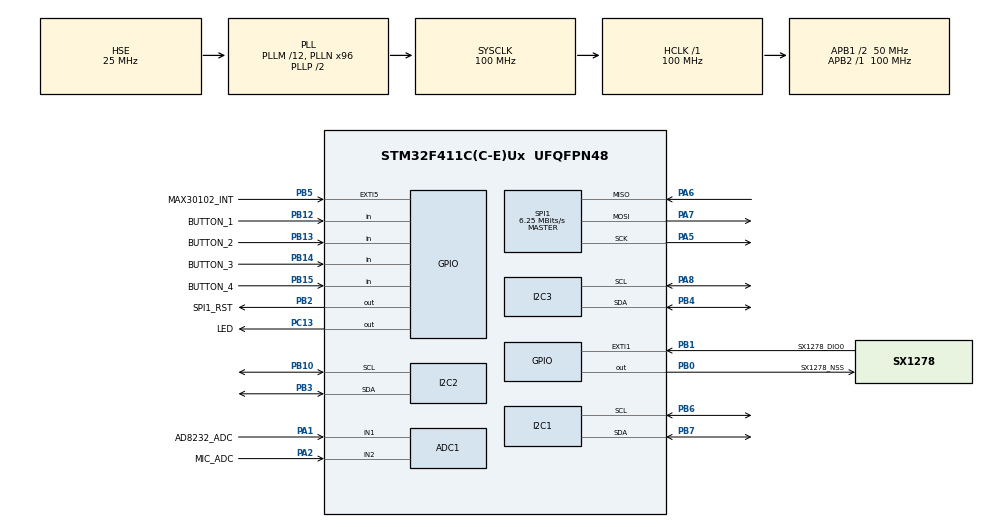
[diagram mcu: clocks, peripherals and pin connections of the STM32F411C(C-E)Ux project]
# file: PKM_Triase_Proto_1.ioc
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ADC1.Channel-1\#ChannelRegularConversion=ADC_CHANNEL_1
ADC1.Channel-2\#ChannelRegularConversion=ADC_CHANNEL_2
ADC1.ContinuousConvMode=DISABLE
ADC1.DMAContinuousRequests=ENABLE
ADC1.ExternalTrigConv=ADC_EXTERNALTRIGCONV_T2_TRGO
ADC1.NbrOfConversion=2
ADC1.NbrOfConversionFlag=1
ADC1.Rank-1\#ChannelRegularConversion=1
ADC1.Rank-2\#ChannelRegularConversion=2
ADC1.SamplingTime-1\#ChannelRegularConversion=ADC_SAMPLETIME_15CYCLES
ADC1.SamplingTime-2\#ChannelRegularConversion=ADC_SAMPLETIME_15CYCLES
ADC1.ScanConvMode=ENABLE
ADC1.master=1
Dma.ADC1.0.Direction=DMA_PERIPH_TO_MEMORY
Dma.ADC1.0.FIFOMode=DMA_FIFOMODE_DISABLE
Dma.ADC1.0.Instance=DMA2_Stream0
Dma.ADC1.0.MemDataAlignment=DMA_MDATAALIGN_HALFWORD
Dma.ADC1.0.MemInc=DMA_MINC_ENABLE
Dma.ADC1.0.Mode=DMA_CIRCULAR
Dma.ADC1.0.PeriphDataAlignment=DMA_PDATAALIGN_HALFWORD
Dma.ADC1.0.PeriphInc=DMA_PINC_DISABLE
Dma.ADC1.0.Priority=DMA_PRIORITY_LOW
Dma.Request0=ADC1
I2C2.I2C_Mode=I2C_Standard
Mcu.Family=STM32F4
Mcu.Name=STM32F411C(C-E)Ux
Mcu.Package=UFQFPN48
NVIC.ADC_IRQn=true\:0\:0\:false\:false\:true\:true\:true\:true
NVIC.DMA2_Stream0_IRQn=true\:0\:0\:false\:false\:true\:false\:true\:true
NVIC.EXTI9_5_IRQn=true\:0\:0\:false\:false\:true\:true\:true\:true
NVIC.I2C2_ER_IRQn=true\:0\:0\:false\:false\:true\:true\:true\:true
NVIC.I2C2_EV_IRQn=true\:0\:0\:false\:false\:true\:true\:true\:true
NVIC.PriorityGroup=NVIC_PRIORITYGROUP_4
NVIC.TIM1_UP_TIM10_IRQn=true\:0\:0\:true\:false\:true\:true\:true\:true
NVIC.TIM2_IRQn=true\:0\:0\:false\:false\:true\:true\:true\:true
PA1.GPIO_Label=AD8232_ADC
PA1.Signal=ADCx_IN1
PA2.GPIO_Label=MIC_ADC
PA2.Signal=ADCx_IN2
PA5.Mode=Full_Duplex_Master
PA5.Signal=SPI1_SCK
PA6.Mode=Full_Duplex_Master
PA6.Signal=SPI1_MISO
PA7.Mode=Full_Duplex_Master
PA7.Signal=SPI1_MOSI
PA8.GPIO_Pu=GPIO_NOPULL
PA8.Mode=I2C
PA8.Signal=I2C3_SCL
PB0.GPIO_Label=SX1278_NSS
PB0.PinState=GPIO_PIN_SET
PB0.Signal=GPIO_Output
PB1.GPIO_Label=SX1278_DIO0
PB1.Signal=GPXTI1
PB10.Mode=I2C
PB10.Signal=I2C2_SCL
PB12.GPIO_Label=BUTTON_1
PB12.GPIO_PuPd=GPIO_PULLUP
PB12.Signal=GPIO_Input
PB13.GPIO_Label=BUTTON_2
PB13.GPIO_PuPd=GPIO_PULLUP
PB13.Signal=GPIO_Input
PB14.GPIO_Label=BUTTON_3
PB14.GPIO_PuPd=GPIO_PULLUP
PB14.Signal=GPIO_Input
PB15.GPIO_Label=BUTTON_4
PB15.GPIO_PuPd=GPIO_PULLUP
PB15.Signal=GPIO_Input
PB2.GPIO_Label=SPI1_RST
PB2.PinState=GPIO_PIN_SET
PB2.Signal=GPIO_Output
PB3.Mode=I2C
PB3.Signal=I2C2_SDA
PB4.GPIO_Pu=GPIO_NOPULL
PB4.Mode=I2C
PB4.Signal=I2C3_SDA
PB5.GPIO_Label=MAX30102_INT
PB5.GPIO_ModeDefaultEXTI=GPIO_MODE_IT_FALLING
PB5.GPIO_PuPd=GPIO_PULLUP
PB5.Signal=GPXTI5
PB6.GPIO_Pu=GPIO_NOPULL
PB6.Mode=I2C
PB6.Signal=I2C1_SCL
PB7.GPIO_Pu=GPIO_NOPULL
PB7.Mode=I2C
PB7.Signal=I2C1_SDA
PC13-ANTI_TAMP.GPIO_Label=LED
PC13-ANTI_TAMP.Signal=GPIO_Output
PC14-OSC32_IN.Mode=LSE-External-Oscillator
PC14-OSC32_IN.Signal=RCC_OSC32_IN
PC15-OSC32_OUT.Mode=LSE-External-Oscillator
PC15-OSC32_OUT.Signal=RCC_OSC32_OUT
PH0\ -\ OSC_IN.Mode=HSE-External-Oscillator
PH0\ -\ OSC_IN.Signal=RCC_OSC_IN
PH1\ -\ OSC_OUT.Mode=HSE-External-Oscillator
PH1\ -\ OSC_OUT.Signal=RCC_OSC_OUT
ProjectManager.HeapSize=0x200
ProjectManager.StackSize=0x400
ProjectManager.TargetToolchain=STM32CubeIDE
RCC.48MHZClocksFreq_Value=40000000
RCC.AHBFreq_Value=100000000
RCC.APB1CLKDivider=RCC_HCLK_DIV2
RCC.APB1Freq_Value=50000000
RCC.APB1TimFreq_Value=100000000
RCC.APB2Freq_Value=100000000
RCC.APB2TimFreq_Value=100000000
RCC.CortexFreq_Value=100000000
RCC.HCLKFreq_Value=100000000
RCC.HSE_VALUE=25000000
RCC.HSI_VALUE=16000000
RCC.PLLM=12
RCC.PLLN=96
RCC.PLLQ=5
RCC.PLLSourceVirtual=RCC_PLLSOURCE_HSE
RCC.SYSCLKFreq_VALUE=100000000
RCC.SYSCLKSource=RCC_SYSCLKSOURCE_PLLCLK
RCC.VCOOutputFreq_Value=200000000
SH.ADCx_IN1.0=ADC1_IN1,IN1
SH.ADCx_IN2.0=ADC1_IN2,IN2
SPI1.BaudRatePrescaler=SPI_BAUDRATEPRESCALER_16
SPI1.CalculateBaudRate=6.25 MBits/s
SPI1.Direction=SPI_DIRECTION_2LINES
SPI1.Mode=SPI_MODE_MASTER
SPI1.VirtualType=VM_MASTER
STMicroelectronics.X-CUBE-ALGOBUILD.1.5.0.LibraryCcDSPOoLibraryJjDSPOoLibrary=true
TIM10.Period=7500
TIM10.Prescaler=999
TIM2.Period=199
TIM2.Prescaler=999
TIM2.TIM_MasterOutputTrigger=TIM_TRGO_UPDATE
VP_STMicroelectronics.X-CUBE-ALGOBUILD_VS_DSPOoLibraryJjLibrary_1.5.0_1.5.0.Mode=DSPOoLibraryJjLibrary
VP_TIM10_VS_ClockSourceINT.Mode=Enable_Timer
VP_TIM2_VS_ClockSourceINT.Mode=Internal
board=custom

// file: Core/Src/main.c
/* USER CODE BEGIN Header */
/**
 ******************************************************************************
 * @file           : main.c
 * @brief          : Main program body
 ******************************************************************************
 * @attention
 *
 * Copyright (c) 2026 STMicroelectronics.
 * All rights reserved.
 *
 * This software is licensed under terms that can be found in the LICENSE file
 * in the root directory of this software component.
 * If no LICENSE file comes with this software, it is provided AS-IS.
 *
 ******************************************************************************
 */
/* USER CODE END Header */
#include "main.h"
#include "adc.h"
#include "dma.h"
#include "i2c.h"
#include "spi.h"
#include "tim.h"
#include "gpio.h"

/* USER CODE BEGIN Includes */
#include <string.h>
#include "stdint.h"
#include "LoRa.h"
#include "dsp_utils.h"
#include "lora_poll.h"
#include "lora_vital.h"
#include "max30102_for_stm32_hal.h"
#include "rfid_pn532.h"
#include "tb_buttons.h"
#include "tb_regs.h"
#include "tb_slave.h"
//#include "filter_1.h"
/* USER CODE END Includes */

/* USER CODE BEGIN PTD */
/* The LoRa uplink packet is lora_vital_t, defined in Core/Inc/lora_vital.h so
 * the receiving station can include the same file rather than transcribe
 * offsets out of here. Age and gender used to live in the packet and are gone:
 * nothing on this board collects them, the MQTT vital has no key for them, and
 * manual patient input belongs to the ESP32 anyway. */
/* USER CODE END PTD */

/* USER CODE BEGIN PD */
// ADC DMA buffer indices (0-based positions in the scan sequence, NOT the
// HAL "Rank" numbers, which are 1-based). Rank 1 = ADC1_IN1 (PA1, AD8232 ECG),
// Rank 2 = ADC1_IN2 (PA2, breathing-sound microphone).
//
// ECG moved from PA0 to PA1 on 2026-08-14. PA0 is the onboard USER KEY on
// WeAct Black Pill boards, so that button circuit shares the net with the
// analogue input. The symptom was mon_ecg_raw pinned at ~4025 counts (3.24V of
// 3.3V) with only a few LSB of hash on it, identical across two different
// AD8232 modules and unaffected by electrode placement - i.e. not a signal at
// all. PA1 has no onboard function. These indices are unchanged by the move:
// the ranks kept their order, only Rank 1's channel changed.
#define ECG_ADC_INDEX 0u
#define MIC_ADC_INDEX 1u
#define ANALOG_CHANNEL_COUNT 2u
// How many raw ADC samples the boxcar in HAL_ADC_ConvCpltCallback averages into
// one ECG value for the ESP32's waveform block. 500Hz / 5 = 100Hz, i.e. exactly one
// per PPG sample at TB_PPG_FS_HZ; the static assert next to max30102_plot proves
// the two still line up. Nothing else may use this rate - the STM32's own ECG
// window keeps the full 500Hz stream.
#define ECG_WAVE_DECIM 5u
// ECG window: DSP_ECG_WINDOW samples at DSP_ADC_FS_HZ = 6.03s, enough for 4-6
// beats and so 3-5 R-R intervals to take a median over.
#define ECG_BUFFER_SIZE DSP_ECG_WINDOW
// LoRa config.
//
// NODE_ID is this node's radio address and its identity on MQTT: the station
// maps it to the topic segment as node-%02u, so address 1 publishes under
// node-01. It must be 1..LORA_POLL_NODE_MAX and unique on the channel -- 0 is
// reserved (byte 0 of a poll is always 0, which is how a node tells a downlink
// from another node's reply). Every physical node needs its own value.
//
// IT IS NO LONGER A BUILD-TIME CONSTANT, and the reason is that the build-time
// version never worked. The value here was committed as 1, nothing in any build
// path ever overrode it -- the Makefile passes no -DNODE_ID and .cproject has
// zero occurrences -- so every board ever flashed from this repository is node 1.
// Two of them on one station is a capture-effect lottery: whichever reply is
// stronger passes CRC, it carries the node_id the station polled for, and two
// patients' vitals alternate under one MQTT identity. Nothing anywhere reports
// it. That is the worst failure this system can produce, and per-board build
// configuration is exactly the thing mass production cannot be trusted to do.
//
// So the address comes from the chip's own factory UID, looked up in the table
// at k_node_uids (further down, next to ServiceLoRaPoll). One binary, every
// board, no per-board configuration. NodeIdFromUid() is the whole mechanism and
// the comment there is the instructions for adding a board.
//
// PRECEDENCE, highest first: the address set in the ESP32's Menu (TB_REG_HOST_NODE_ID,
// see ResolveHostNodeId), then the UID table, then -DNODE_ID, then 0 = silent.
//
// This define survives as the ESCAPE HATCH for a board that is not in the table
// yet: -DNODE_ID=2 still works and the table still wins over it when it matches.
// It defaults to 0 rather than 1, and 0 means "this board has no address": it
// refuses to transmit and clears TB_SENSOR_LORA so the ESP32's status dot shows
// it. A board that says nothing is diagnosable from one screen; a second board
// answering as node 1 quietly corrupts another patient's record.
//
// LORA_FREQUENCY and NODE_REPORT_INTERVAL are gone. The first was dead code:
// the library takes MHz (hlora.frequency = 433 from newLoRa()) and never read
// this define, so "fixing" it would have moved the node off the station's
// channel. The second described the old free-running transmit, which no longer
// exists -- and it never matched TIM10's actual 75ms period either.
//
// LORA_TX_TIMEOUT must stay strictly under LORA_POLL_SLOT_MS (250ms): a reply
// still being retried past the slot lands in the NEXT node's slot and destroys
// that node's reply too. 100ms is above the ~82ms worst-case airtime and well
// under the slot, so a stuck transmit gives up inside its own window.
#ifndef NODE_ID /* -DNODE_ID=N only for a board not yet in k_node_uids */
#define NODE_ID 0u
#else
/* Only the override is checkable at compile time. A typo'd -DNODE_ID is
 * silent on a radio in both directions: 0 answers every node's poll (see
 * lora_poll_for_me), and above the maximum is never polled at all, which looks
 * exactly like a dead node. The table's own ids are bounded at runtime instead
 * -- see NodeIdFromUid(). */
_Static_assert(NODE_ID >= 1u && NODE_ID <= LORA_POLL_NODE_MAX,
		"-DNODE_ID must be 1..LORA_POLL_NODE_MAX; 0 is reserved and above the max is never polled");
#endif
#define LORA_TX_TIMEOUT 100u

// How stale a poll may be before the node declines to answer it. The node
// cannot know when RxDone actually fired -- EXTI1 is not enabled, so the flag is
// noticed by polling -- but it does know when it last looked and saw nothing, so
// the poll's age is bounded by the interval between two consecutive checks, i.e.
// by one superloop pass. That bound is what is tested.
//
// This exists because a LATE REPLY IS WORSE THAN NO REPLY. The station starts
// its LORA_POLL_SLOT_MS window when its poll transmit completes; a reply still
// in the air after that lands inside the NEXT node's slot and destroys that
// node's reply too. One slow node would silently take out its neighbour, which
// is about the most confusing failure this system can produce. Missing our own
// slot costs one reading and the station just counts a miss.
//
// 150ms is chosen to sit above the slowest ordinary pass -- an RFID scan blocks
// ~120ms inside Pn532_Service -- so a scan in progress does not cost every poll,
// while the static assert below keeps deadline + airtime inside the slot.
#define LORA_REPLY_DEADLINE_MS 150u

// Worst-case airtime for the reply. 41 bytes now (LORA_VITAL_FIXED_LEN 21 plus a
// full 20-character tag) at SF7/BW125/CR4-5 with an 8-symbol preamble: 13 payload
// blocks, 73 symbols, ~87ms with the preamble. Only used to prove the timing
// budget at compile time.
//
// The three fields LORA_VITAL_VERSION 0x02 appended cost 5ms of that -- 82ms at 38
// bytes, 87ms at 41 -- because they pushed the payload over another 4-byte block
// boundary. 90 still bounds it, but by 3ms rather than 8, so the next field added
// to lora_vital_t has to be weighed against THIS constant and the assert below,
// not just against the struct.
#define LORA_REPLY_AIRTIME_MS 90u

/* RegIrqFlags bit 5, PayloadCrcError. The LoRa library clears the whole flags
 * register without looking at this bit, so a corrupt frame is read out as
 * garbage and reaches the caller looking like a real packet. Tested here before
 * LoRa_receive() gets a chance to clear it. */
#define LORA_IRQ_CRC_ERROR 0x20u

/* USER CODE END PD */

/* USER CODE BEGIN PV */
static volatile uint16_t mon_adc_min = 0;
static volatile uint16_t mon_adc_max = 4096;
// LoRa
LoRa hlora;

/* The packet as last transmitted. No separate serialisation buffer: the struct
 * is packed and little-endian, so it already IS the wire image, and PackTelemetry
 * fills it immediately before the transmit -- a memcpy of it to a char array
 * bought a copy and nothing else. Named mon_ so CubeMonitor's variable filter
 * lists it with everything else the firmware produces. */
lora_vital_t mon_lora_vital;
uint16_t lora_status;

// SPO2
max30102_t hmax30102;

// Analog Sensor
static volatile uint16_t analog_data[ANALOG_CHANNEL_COUNT];
// ECG double buffer: the ADC ISR fills one half while the main loop processes
// the other, so a 6.03s window can be analysed without blocking acquisition.
// 3 buffers x DSP_ECG_WINDOW: these two banks at 2B/sample plus dsp_utils.c's
// mon_ecg_filtered and ecg_energy at 4B each = 12B per sample, 36kB at 3000.
static uint16_t ecg_buffer[2][ECG_BUFFER_SIZE];
static volatile uint8_t ecg_fill_bank = 0;
static volatile uint16_t ecg_buffer_index = 0;
static volatile uint8_t ecg_ready_bank = 0xFF; /* 0xFF = none pending */

/* ---- Monitored outputs -------------------------------------------------- */
/* Every value the firmware produces, in one place, for STM32CubeMonitor.
 * CubeMonitor reads these out of RAM over SWD using the DWARF info in the
 * .elf, so they need two properties: external linkage (no `static`), so the
 * names are unambiguous in the variable picker and survive any inlining, and
 * `volatile`, so the compiler cannot discard a store that nothing inside the
 * firmware ever reads back. The mon_ prefix means typing "mon_" in the
 * variable filter lists exactly these and nothing else.
 *
 * Reads are not atomic: a 32-bit float sampled mid-update can momentarily
 * show a torn value. Harmless for monitoring, not safe to log as truth. */

/* Raw inputs, updated at the acquisition rate. */
volatile uint16_t mon_ecg_raw = 0; /**< 500Hz raw ECG sample, ADC LSB */
volatile uint16_t mon_mic_raw = 0; /**< 500Hz raw mic sample, ADC LSB */
/* The ECG as the ESP32 gets it: mon_ecg_raw averaged over 5 consecutive samples,
 * so 500/5 = 100 Hz -- one value per PPG sample, which is what lets the two
 * share a slot in the waveform block. Still raw ADC counts, not filtered: the
 * boxcar is a decimation anti-alias, and everything the BP model wants from this
 * channel (the R peak's position) survives it. Watch it against mon_ecg_raw; the
 * shapes must match with the hash taken off.
 *
 * mon_ecg_staged_valid stays 0 until the first five samples have arrived, which
 * is 10 ms after the ADC starts. It exists because 0 counts is a legal reading
 * (an input on the bottom rail), so the value alone cannot say "nothing staged
 * yet" -- and if this ever reads 0 with mon_adc_samples climbing, the boxcar
 * below is the thing that stopped, not the ADC. */
volatile uint16_t mon_ecg_staged = 0;
volatile uint8_t mon_ecg_staged_valid = 0;
volatile uint32_t mon_ir_raw = 0; /**< latest MAX30102 IR count */
volatile uint32_t mon_red_raw = 0; /**< latest MAX30102 RED count */
/* Same two channels after the 10Hz linear-phase FIR, plus the IR pulse with
 * its baseline subtracted. These are the PPG the rest of the system should
 * work from - the raw stream carries ~25 counts of hash on a ~200-count pulse,
 * which buries the shape. Plot mon_ppg_ir_smooth against mon_ir_raw to see what
 * the filter removed. All three lag the raw stream by a constant 15 samples
 * (150ms), and the delay is the same at every frequency, so the waveform is
 * shifted rather than deformed. */
volatile float mon_ppg_ir_smooth = 0.0f;
volatile float mon_ppg_red_smooth = 0.0f;
volatile float mon_ppg_pulse = 0.0f;
/* The IR pulse as a percentage of its own baseline: the normalised PPG, and the
 * trace to plot when the amplitude has to mean something. mon_ppg_pulse is in
 * ADC counts, so its height moves with LED current, sensor distance and how
 * hard the finger presses; this one divides all three out and reads 0.5-2%
 * peak-to-peak on any seated finger. Expect a flat 0 with no finger, and a few
 * seconds of nonsense after boot while the 0.5Hz baseline settles.
 *
 * Also the sanity check on mon_spo2_perfusion, which is this same quantity
 * averaged as RMS over a 1.28s block: if perfusion reads far below the height
 * of this trace, the block was dominated by something that is not the pulse. */
volatile float mon_ppg_norm_pct = 0.0f;
/* 1 when the smoothed RED channel is at or above DSP_PPG_MIN_DC, i.e. a finger
 * is on the sensor. Published as TB_FLAG_PPG_CONTACT. Watch it against
 * mon_ppg_red_smooth: with nothing on the sensor red sits around 2000 counts,
 * and a seated finger gives 150000-180000, so this should be an unambiguous
 * 0 or 1 and not flicker. If it does flicker, the finger is not seated. */
volatile uint8_t mon_ppg_contact = 0;

/* ECG / heart rate, updated once per 4s window. */
volatile uint16_t mon_hr_bpm = 0; /**< 0 = no plausible rate found */
volatile uint8_t mon_ecg_beats = 0; /**< R-peaks in the last window */
volatile uint16_t mon_ecg_mean = 0; /**< raw ADC mean, electrode-contact hint */
volatile float mon_ecg_rms = 0.0f; /**< 5-15Hz RMS, signal-quality hint */

/* Pulse rate from the PPG, updated once per 1.28s SpO2 block over a rolling 4s
 * of pulse waveform. This is NOT mon_hr_bpm measured a second way: HR counts
 * electrical depolarisations at the chest, PR counts mechanical pulses arriving
 * at the finger, so a beat too weak to open the aortic valve is in HR and not
 * here. On a perfusing patient they agree within a beat or two, and a standing
 * gap between them is a pulse deficit rather than a bug in either.
 *
 * Watch all four together, because 0 means three different things:
 *   pulses 0            -> no pulse found at all (no finger, or no perfusion)
 *   pulses >0, spread >0.30 -> peaks found, spacing inconsistent: motion, or a
 *                          genuinely irregular rhythm. A PPG cannot tell those
 *                          apart, which is why no number is published.
 *   regular 1, bpm 0    -> rate outside 30-220, i.e. measured and implausible.
 * Under 40bpm expect 0 regardless: 4s holds fewer than the 3 intervals the
 * median needs. */
volatile uint16_t mon_pr_bpm = 0;
volatile uint8_t mon_pr_pulses = 0;
volatile uint8_t mon_pr_regular = 0;
volatile float mon_pr_spread = 0.0f;
/* Intervals that agreed with the median. Read with mon_pr_pulses: agree ==
 * pulses-1 is a clean window, and a shortfall is the number of artefacts the
 * median absorbed while still publishing a rate. This is the pair that shows
 * whether the sensor mount is good, which mon_pr_spread alone cannot: after the
 * majority gate, a large spread with regular 1 is a forgiven knock, not a
 * fault. */
volatile uint8_t mon_pr_agree = 0;
/* What actually goes on the wire as "hr": mon_hr_bpm when the ECG is producing
 * one, mon_pr_bpm otherwise. Kept as its own variable rather than computed at
 * each of the three publish sites, because three copies of a fallback rule
 * eventually disagree and the disagreement looks like a link bug.
 * mon_rate_is_pr says which source won, so a rate on the screen is always
 * traceable to a sensor. */
volatile uint16_t mon_rate_bpm = 0;
volatile uint8_t mon_rate_is_pr = 0;
/* How many times the two rate sources disagreed by more than 25% and the ECG was
 * dropped. Climbing while a finger is on the sensor means the ECG electrodes are
 * off or noisy -- the closest thing to a lead-off indicator until AD8232's LO pin
 * reaches a GPIO. See the cross-check in the superloop. */
volatile uint32_t mon_rate_disagreements = 0;

/* Respiratory rate, updated every 2.5s once the 25.6s window has filled. */
volatile float mon_resp_brpm = 0.0f; /**< breaths/min, 0 = no reading */
/* Respiratory diagnostics. A breath is audible twice per cycle (inhale and
 * exhale), so the envelope's strongest component is usually at 2x the true
 * rate. mon_resp_peak_brpm is that raw spectral peak before correction, and
 * mon_resp_halved says whether it was folded in half to get mon_resp_brpm.
 * If mon_resp_brpm looks like double or half the real rate, these two show
 * which way the decision went. mon_resp_peak_ratio under 3.0 means the peak
 * did not stand clear of the noise and the window was rejected. */
volatile float mon_resp_peak_brpm = 0.0f;
volatile uint8_t mon_resp_halved = 0;
volatile uint8_t mon_resp_subharmonic = 0;
volatile float mon_resp_peak_ratio = 0.0f;
/* The DSP_RESP_TOP_N strongest spectral peaks, descending by magnitude. Plot
 * these as a group in CubeMonitor to see the whole envelope spectrum: a real
 * breath gives one dominant peak plus its harmonic at 2x, while room noise
 * gives several peaks of similar magnitude at unrelated frequencies. */
volatile float mon_resp_top_brpm[DSP_RESP_TOP_N];
volatile float mon_resp_top_mag[DSP_RESP_TOP_N];

/* SpO2, updated once per 128-sample (1.28s) PPG block. */
volatile float mon_spo2_pct = 0.0f;
volatile float mon_spo2_r = 0.0f; /**< ratio-of-ratios behind the % above */
volatile uint8_t mon_spo2_valid = 0;
/* Diagnostics: why a block was rejected, and the numbers behind the decision.
 * mon_spo2_reject is a Dsp_Spo2Reject: 0=OK, 2=DC too low (no finger),
 * 3=perfusion too low (finger present but no pulse detected), 4=R out of
 * range, 5=result under 70%. mon_spo2_perfusion should be 0.005-0.02 on a
 * properly seated finger. These are filled on every block, valid or not. */
volatile uint8_t mon_spo2_reject = 0;
volatile float mon_spo2_ir_dc = 0.0f;
volatile float mon_spo2_red_dc = 0.0f;
volatile float mon_spo2_ir_ac = 0.0f;
volatile float mon_spo2_red_ac = 0.0f;
volatile float mon_spo2_perfusion = 0.0f;
/* Counts how many consecutive blocks have been rejected. Climbing steadily
 * means the sensor is being read but never producing a usable reading. */
volatile uint32_t mon_spo2_rejects = 0;

/* Liveness counters. If mon_adc_samples is not climbing the DMA has stalled;
 * if mon_ecg_windows is not climbing the main loop is stuck or starved. */
volatile uint32_t mon_adc_samples = 0;
volatile uint32_t mon_ecg_windows = 0;
volatile uint32_t mon_lora_frames = 0;

/* LoRa link diagnostics. The link fails silently -- a mismatched radio
 * parameter or sync word produces no error anywhere, just nothing -- so these
 * counters are the only way to tell the failures apart from CubeMonitor:
 *
 *   rx == 0                  nothing is being heard at all. The station is not
 *                            transmitting, or the two radios disagree about
 *                            frequency/SF/BW/CR/sync word. Diff the modem
 *                            registers before suspecting the protocol.
 *   rx climbing, polls == 0  packets arrive but none are for this node. Either
 *                            mon_node_id is 0 (this board's UID is not in the
 *                            table, so it answers nothing -- check that first) or
 *                            it is outside the range the station polls, or these
 *                            are other nodes' replies (normal on a shared
 *                            channel), or LORA_POLL_VERSION differs between the
 *                            two copies of lora_poll.h.
 *   crc climbing             somebody is transmitting and the link is marginal.
 *                            This is the one antenna work fixes. The library
 *                            ignores the CRC flag, so without this counter a
 *                            corrupt frame is indistinguishable from a good one.
 *   stale climbing           polls are arriving but the superloop noticed them
 *                            too late to answer inside the slot, so the reply
 *                            was deliberately not sent. From the station this
 *                            looks exactly like a dead node, which is why it is
 *                            counted here rather than left to inference.
 *   polls > frames + stale   the reply transmit is timing out. Check that the
 *                            antenna is attached; TX into an open PA can hang.
 *
 * mon_lora_reply_ms is the last poll-to-transmit-done latency in ms. The whole
 * design rests on it staying well under LORA_POLL_SLOT_MS (250), so it is the
 * one number to look at before believing the timing contract holds.
 *
 * mon_lora_rssi is the last poll's RSSI in dBm, UNCLAMPED -- int16_t because
 * LoRa_getRSSI() can legitimately return values outside int8_t, and seeing the
 * raw figure here is more useful than seeing it pinned. The clamped copy is what
 * goes to the ESP32; see the latch in ServiceLoRaPoll(). */
volatile uint32_t mon_lora_rx = 0;
volatile uint32_t mon_lora_polls = 0;
volatile uint32_t mon_lora_crc = 0;
volatile uint32_t mon_lora_stale = 0;
volatile uint32_t mon_lora_reply_ms = 0;
volatile int16_t mon_lora_rssi = 0;
/* This node's radio address and MQTT identity, resolved once at boot from the
 * factory UID -- see NodeIdFromUid(). 0 means NO ADDRESS: this board's UID is not
 * in the table and no -DNODE_ID was given, so it answers no poll and clears
 * TB_SENSOR_LORA. The first thing to read when a node never appears on the
 * dashboard. */
volatile uint8_t mon_node_id = 0;

/* ---- ESP32 I2C link ----------------------------------------------------- */
/* Debounce state for the 4 front-panel buttons. The published byte is
 * mon_buttons (1 = pressed, bit0 = BUTTON_1); watch it in CubeMonitor to check
 * wiring without needing the ESP32 attached. */
static tb_buttons_t btn_state;
volatile uint8_t mon_buttons = 0;
/* The two bitmasks PublishToEsp32 computes, kept so the LoRa packet can carry
 * the same ones the ESP32 sees. TB_FLAG_* and TB_SENSOR_*. */
volatile uint8_t mon_flags = 0;
volatile uint8_t mon_sensor_ok = 0;
/* Last command the ESP32 asked for, latched for visibility. Acting on these is
 * the next step; right now they are only counted so the link can be proven in
 * both directions before any behaviour depends on it. */
volatile uint8_t mon_last_cmd = 0;
volatile uint32_t mon_cmds = 0;
/* Triage result written back by the ESP32, in LoRa order (0=BLACK 1=RED
 * 2=YELLOW 3=GREEN) and copied straight into the uplink packet. Starts at
 * LORA_VITAL_PRIORITY_NONE, not 0: 0 is BLACK, so a packet sent before the ESP32
 * has scored anything would report the patient as dead. */
volatile uint8_t mon_priority = LORA_VITAL_PRIORITY_NONE;
volatile uint8_t mon_confidence = 0;
/* The model's raw ESI, 1..5, taken WITH the verdict above and sticky with it.
 * LORA_VITAL_ESI_NONE (0) means the model refused to score, which is the same
 * condition that leaves mon_priority at NONE -- the two always move together, and
 * ForgetPatient() clears all three, because a score for a patient who has left
 * describes nobody. */
volatile uint8_t mon_esi = LORA_VITAL_ESI_NONE;
/* Blood pressure as predicted by the ESP32's ML model and written back over I2C
 * (TB_REG_HOST_BP_SYS/DIA), in mmHg. STICKY, like mon_priority above and for the
 * same reason: a vital transmitted between predictions should carry the standing
 * pressure rather than drop to "no reading", and both links must show the same
 * pair -- the LoRa packet and the I2C snapshot are built from these two variables
 * and never from a second take.
 *
 * 0/0 with mon_bp_valid clear until the first validated pair arrives, which is
 * what keeps TB_FLAG_BP_VALID honest at boot. Once set, mon_bp_valid never goes
 * back to 0: a model that has spoken has given this node a reading, and there is
 * no staleness rule here to un-say it. Rejected pairs never reach these (see
 * mon_bp_writes_rejected in tb_slave.c), so a bad prediction leaves the last good
 * one standing rather than blanking the field. */
volatile uint16_t mon_bp_sys = 0;
volatile uint16_t mon_bp_dia = 0;
volatile uint8_t mon_bp_valid = 0;
/* How many validated pairs have arrived. The one number that separates "the
 * ESP32 is not writing" from "the ESP32 is writing values the range test throws
 * away" -- read it beside mon_bp_writes_rejected. */
volatile uint32_t mon_bp_updates = 0;

/* ---- RFID (PN532 on I2C3) ------------------------------------------------ */
/* The tag as ASCII hex, which is what goes on the wire and onto the ESP32's
 * screen. Uppercase, no separators: "04A2B3C4". Not NUL-terminated on the wire,
 * so rfid_ascii_len is authoritative. */
static char rfid_ascii[TB_RFID_MAX];
static uint8_t rfid_ascii_len;
/* Set by TB_CMD_START_SCAN, cleared when a tag is found, when the ESP32 aborts,
 * or when RFID_SCAN_WINDOW_MS expires.
 *
 * Why a retry window and not a single poll: the ESP32 asks to scan once, but the
 * operator presents the card seconds later. One PN532 poll would look at an
 * empty field, report NO_CARD and give up -- exactly what "nothing happened when
 * I tapped the card" looks like.
 *
 * Why the window is bounded rather than waiting for TB_CMD_ABORT: the ESP32 does
 * not send ABORT today. Without a deadline, a scan nobody completes would retry
 * forever, and each attempt blocks the superloop ~120 ms, so the ECG and SpO2
 * paths would stay permanently starved after one unanswered scan. The window is
 * generous enough for a person to find their card and short enough that a
 * forgotten scan heals itself. */
#define RFID_SCAN_WINDOW_MS 30000u
static uint8_t rfid_scanning;
static uint32_t rfid_scan_started_ms;
/* CubeMonitor view of the last scan. mon_rfid_status is a Pn532_Status:
 * 0=IDLE 1=FOUND 2=NO_CARD 3=ERR_I2C 4=ERR_ABSENT 5=ERR_PROTO. 4 means nothing
 * ACKed address 0x24 at all -- bus mode strap, wiring or supply. 5 means it did
 * ACK and then failed to answer properly, which points at the module's own
 * power rail rather than the bus. */
volatile uint8_t mon_rfid_status = 0;
volatile uint8_t mon_rfid_uid_len = 0;
volatile uint8_t mon_rfid_uid[PN532_UID_MAX] = { 0 };
/* Which handshake step the last attempt reached (Pn532_Stage), and the raw bytes
 * of the last reply including its I2C status byte. Watch these together: the
 * stage says where it stopped, the bytes say what arrived instead. All 0xFF is
 * an open bus, a leading 0x00 status byte is "module not ready", and a frame
 * that starts a byte or two in is padding the parser now tolerates. */
volatile uint8_t mon_rfid_stage = 0;
volatile uint8_t mon_rfid_raw[PN532_RAW_MAX] = { 0 };
volatile uint8_t mon_rfid_raw_len = 0;
volatile uint32_t mon_rfid_scans = 0;
volatile uint32_t mon_rfid_found = 0;
/* USER CODE END PV */

void SystemClock_Config(void);
/* USER CODE BEGIN PFP */
static void ResolveNodeId(void);
static void PackTelemetry(void);
static void PublishToEsp32(void);
static void ServiceRfid(void);
static void ServiceLoRaPoll(void);
static void ForgetPatient(void);
static uint8_t ResolveHostNodeId(uint8_t host, uint8_t current);
/* USER CODE END PFP */

/* USER CODE BEGIN 0 */
void max30102_plot(uint32_t ir_sample, uint32_t red_sample);
/* USER CODE END 0 */

int main(void)
{

  /* MCU Configuration--------------------------------------------------------*/

  /* Reset of all peripherals, Initializes the Flash interface and the Systick. */
  HAL_Init();

  /* Configure the system clock */
  SystemClock_Config();

  /* Initialize all configured peripherals */
  MX_GPIO_Init();
  MX_DMA_Init();
  MX_ADC1_Init();
  MX_I2C1_Init();
  MX_I2C2_Init();
  MX_SPI1_Init();
  MX_TIM10_Init();
  MX_I2C3_Init();
  MX_TIM2_Init();
  /* USER CODE BEGIN 2 */
	// DSP filter states must be reset before any sample can arrive.
	Dsp_Init();

	// LoRa Init
	memset(&mon_lora_vital, 0, sizeof(mon_lora_vital));

	hlora = newLoRa();

	hlora.CS_port = SX1278_NSS_GPIO_Port;
	hlora.CS_pin = SX1278_NSS_Pin;
	hlora.reset_port = SPI1_RST_GPIO_Port;
	hlora.reset_pin = SPI1_RST_Pin;
	hlora.DIO0_port = SX1278_DIO0_GPIO_Port;
	hlora.DIO0_pin = SX1278_DIO0_Pin;
	hlora.hSPIx = &hspi1;

	HAL_Delay(100);

	lora_status = LoRa_init(&hlora);

	/* Into receive immediately and stay there for the rest of the run. The node
	 * is a slave on this link: it answers polls and never speaks first, so RX
	 * continuous is its resting state and LoRa_transmit() restores whatever mode
	 * it was called in -- which is why nothing has to put the radio back
	 * afterwards.
	 *
	 * Guarded on LORA_OK: LoRa_startReceiving() writes RegOpMode unconditionally,
	 * and driving a radio that failed RegVersion (absent, mis-wired, wrong SPI)
	 * just puts noise on the bus. */
	if (lora_status == LORA_OK) {
		LoRa_startReceiving(&hlora);
	}

	// SPO2 Init
	HAL_I2C_Init(&hi2c1);
	max30102_init(&hmax30102, &hi2c1);
	max30102_reset(&hmax30102);
	max30102_clear_fifo(&hmax30102);

	// FIFO configurations
	max30102_set_fifo_config(&hmax30102, max30102_smp_ave_8, 1, 7);
	// LED and SPO2 configurations
	max30102_set_led_pulse_width(&hmax30102, max30102_pw_16_bit);
	max30102_set_adc_resolution(&hmax30102, max30102_adc_2048);
	max30102_set_sampling_rate(&hmax30102, max30102_sr_800);
	max30102_set_led_current_1(&hmax30102, 6.2f);
	max30102_set_led_current_2(&hmax30102, 6.2f);
	// Enter SpO2 mode
	max30102_set_mode(&hmax30102, max30102_spo2);
	// Enable FIFO_A_FULL interrupt
	max30102_set_a_full(&hmax30102, 1);
	max30102_set_ppg_rdy(&hmax30102, 1);
	// Enable die temperature measurement
	max30102_set_die_temp_en(&hmax30102, 1);
	// Enable DIE_TEMP_RDY interrupt
	max30102_set_die_temp_rdy(&hmax30102, 1);

	// Init ECG and mic ADC DMA
	// Element-wise, not memset: analog_data is volatile and memset would want
	// the qualifier cast away.
	for (uint32_t i = 0; i < ANALOG_CHANNEL_COUNT; ++i) {
		analog_data[i] = 0;
	}
	memset(ecg_buffer, 0, sizeof(ecg_buffer));
	ecg_buffer_index = 0;
	ecg_fill_bank = 0;
	ecg_ready_bank = 0xFF;
	// Start ADC DMA and timing TIM2
	// HAL_ADC_Start_DMA takes uint32_t* for legacy reasons; the DMA itself is
	// configured HALFWORD/HALFWORD, so the uint16_t buffer is what the hardware
	// actually writes. Cast through void* to drop volatile without a warning.
	HAL_ADC_Start_DMA(&hadc1, (uint32_t *) (void *) analog_data,
			ANALOG_CHANNEL_COUNT);
	HAL_TIM_Base_Start(&htim2);

	// RFID: PN532 on I2C3 (PA8 SCL / PB4 SDA). Bind only -- the module is
	// probed lazily on the first scan, so a missing or mis-strapped reader costs
	// nothing at boot and cannot stall startup.
	Pn532_Bind(&hi2c3);

	// ESP32 link: I2C2 slave at TB_I2C_SLAVE_ADDR. Last, so a master read that
	// arrives immediately finds the sensors already streaming.
	tb_buttons_init(&btn_state);
	tb_slave_init();
	// Who is this board? Resolved from the chip's own UID, which tb_slave_init()
	// has already published at TB_REG_UID so a new board can be added to the
	// table with nothing but the ESP32's console. mon_node_id 0 means "not in
	// the table": the node answers no poll rather than claiming somebody's id.
	ResolveNodeId();
	PublishToEsp32();

	mon_adc_min = 0;
	mon_adc_max = 4096;
  /* USER CODE END 2 */

  /* Infinite loop */
	while (1) {

    /* USER CODE BEGIN 3 */
		/* ---- ECG: heart rate from the bank the ISR just finished ---- */
		uint8_t bank = ecg_ready_bank;
		if (bank != 0xFF) {
			Dsp_EcgResult ecg;
			Dsp_EcgProcessWindow(ecg_buffer[bank], ECG_BUFFER_SIZE, &ecg);
			ecg_ready_bank = 0xFF; /* release the bank back to the ISR */

			mon_hr_bpm = ecg.bpm;
			mon_ecg_beats = ecg.beats;
			mon_ecg_mean = ecg.mean_raw;
			mon_ecg_rms = ecg.rms_filtered;
			++mon_ecg_windows;
		}

		/* ---- Respiratory rate from the breathing-sound envelope ---- */
		if (Dsp_RespReady()) {
			Dsp_RespDebug rdbg;
			float brpm = Dsp_RespRateBrpm(&rdbg);
			mon_resp_brpm = brpm;
			mon_resp_peak_brpm = rdbg.peak_brpm;
			mon_resp_halved = rdbg.halved;
			mon_resp_subharmonic = rdbg.subharmonic_found;
			mon_resp_peak_ratio = rdbg.peak_ratio;
			for (uint32_t i = 0; i < DSP_RESP_TOP_N; ++i) {
				mon_resp_top_brpm[i] = rdbg.top_brpm[i];
				mon_resp_top_mag[i] = rdbg.top_mag[i];
			}
		}

		/* ---- SpO2 ---- */
		if (Dsp_Spo2Ready()) {
			Dsp_Spo2Result s;
			Dsp_Spo2Compute(&s);

			/* Always mirror the diagnostics, valid or not. */
			mon_spo2_valid = s.valid;
			mon_spo2_reject = s.reject;
			mon_spo2_ir_dc = s.ir_dc;
			mon_spo2_red_dc = s.red_dc;
			mon_spo2_ir_ac = s.ir_ac;
			mon_spo2_red_ac = s.red_ac;
			mon_spo2_perfusion = s.perfusion;
			mon_spo2_r = s.r_value;

			if (s.valid) {
				mon_spo2_pct = s.spo2_pct;
				mon_spo2_rejects = 0;
			} else if (s.reject == DSP_SPO2_REJ_DC_LOW) {
				/* No finger: blank at once, do not hold. The hold below exists
				 * for AMBIGUOUS blocks -- a noisy one among good ones -- but a
				 * DC floor 30x below a seated finger is not ambiguous, it is the
				 * operator taking their hand off. Holding a stale percentage for
				 * 4s after that is how a number ends up attributed to the wrong
				 * patient, so it is the one reject that must not be smoothed. */
				mon_spo2_pct = 0.0f;
				mon_spo2_rejects = 0;
			} else {
				++mon_spo2_rejects;
				/* Hold the last good percentage on screen rather than blanking
				 * it: a single noisy 1.28s block among good ones would
				 * otherwise look like the reading collapsing to zero. Only
				 * declare no-reading after ~4s of consecutive rejects, which
				 * is a genuine loss of signal. mon_spo2_valid still goes 0
				 * immediately, so the staleness is always visible. */
				if (mon_spo2_rejects >= 3U) {
					mon_spo2_pct = 0.0f;
				}
			}

			/* ---- Pulse rate, on the same block boundary ---- */
			/* Gated on the numbers Dsp_Spo2Compute just returned rather than on
			 * s.valid: SpO2 can be rejected for reasons that say nothing about
			 * whether a rate is countable (R out of range, an uncalibrated
			 * percentage below 70), and refusing a good pulse rate because the
			 * ratio-of-ratios was unhappy would throw away the one vital still
			 * working. What a rate does need is a finger (DC) and a pulse
			 * (perfusion), which are exactly the first two gates.
			 *
			 * Both thresholds are the SpO2 path's own constants, deliberately:
			 * "is there a finger with a pulse on the sensor" is one physical
			 * question and must not acquire a second set of limits that can
			 * drift apart from the first. */
			if (s.ir_dc >= DSP_PPG_MIN_DC && s.perfusion >= DSP_SPO2_MIN_PI) {
				Dsp_PrResult pr;
				Dsp_PrCompute(&pr);
				mon_pr_bpm = pr.bpm;
				mon_pr_pulses = pr.pulses;
				mon_pr_regular = pr.regular;
				mon_pr_spread = pr.spread;
				mon_pr_agree = pr.agree;
			} else {
				/* No hold here, unlike SpO2 above. A rate is only as good as the
				 * contact it was measured through, and the 4s ring is already an
				 * average - holding a stale one on top of that would put a
				 * number on screen up to 8s after the finger left. */
				mon_pr_bpm = 0;
				mon_pr_pulses = 0;
				mon_pr_regular = 0;
				mon_pr_spread = 0.0f;
				mon_pr_agree = 0;
			}
		}

		/* The rate the rest of the system sees. Recomputed every pass, not
		 * inside either producer's block, so neither source can stall the
		 * other's updates: if the MAX30102 stops answering, PPG blocks stop
		 * completing, and a fresh ECG rate must still reach the wire.
		 *
		 * The choice itself lives in Dsp_PickRate() so it is host-tested -- see
		 * tools/tb_link_selftest.c. It is not "prefer the ECG": read the comment
		 * there before changing the 25% window, it is measured, not guessed. */
		{
			uint8_t from_ppg = 0U;

			mon_rate_bpm = Dsp_PickRate(mon_hr_bpm, mon_pr_bpm, &from_ppg);
			mon_rate_is_pr = from_ppg;

			/* The ECG had a rate and still lost, so the two sensors disagreed.
			 * The closest thing to a lead-off indicator this board has. */
			if ((mon_hr_bpm > 0U) && (from_ppg != 0U)) {
				++mon_rate_disagreements;
			}
		}

		/* ---- LoRa: answer the station if it asked ---- */
		mon_node_id = ResolveHostNodeId(tb_slave_host_node_id(), mon_node_id);
		ServiceLoRaPoll();

		// Prefer the interrupt path, but fall back to polling if the edge never arrives
		if (max30102_has_interrupt(&hmax30102)) {
			max30102_interrupt_handler(&hmax30102);
		} else {
			max30102_read_fifo(&hmax30102);
		}

		/* ---- ESP32 link ----
		 *
		 * Order matters: take the command first, so a START_SCAN arriving this
		 * pass is serviced this pass, and publish last, so the tag it found is
		 * in the very next snapshot the ESP32 reads. The other way round costs
		 * two full loops of latency on every scan. */
		tb_slave_service(); /* unwedge the bus first, or none of the rest lands */
		{
			uint8_t cmd = tb_slave_take_cmd();
			if (cmd != TB_CMD_NONE) {
				/* START_SCAN and ABORT are acted on; gating the measure window on
				 * START_MEASURE and parking sensors on POWER_OFF is the next step --
				 * a half-wired command that silently does nothing is worse than one
				 * that visibly does. */
				if (cmd == TB_CMD_START_SCAN) {
					rfid_scanning = 1U;
					rfid_scan_started_ms = HAL_GetTick();
					/*
					 * A new patient inherits nothing -- see ForgetPatient().
					 *
					 * The tag in particular: without clearing it, the previous
					 * patient's card is still in the snapshot when the ESP32 opens
					 * its scanning screen, and the scan "succeeds" instantly on a
					 * stale identifier. That is the worst failure mode here, since
					 * it attaches one patient's telemetry to another's ID.
					 *
					 * Done here rather than trusting an ABORT to have arrived
					 * first, so no command ordering can leave anything standing.
					 */
					ForgetPatient();
				} else if (cmd == TB_CMD_ABORT) {
					rfid_scanning = 0U;
					/*
					 * The patient has left the node. This is the other half of the
					 * bug above and the one that shows up on the dashboard: the
					 * station publishes a vital for as long as a triage verdict
					 * stands, so a sticky verdict means this node keeps reporting a
					 * patient who is gone, every 15 s, with every measurement blank
					 * because nobody is on the sensors. Those blanks are the newest
					 * readings the backend has, so they bury the real measurement.
					 *
					 * Clearing the verdict makes the station withhold the vital
					 * entirely (it omits an unscored packet), while node status keeps
					 * being published every cycle -- so the node stays ONLINE and
					 * only the patient data stops.
					 */
					ForgetPatient();
				}
				mon_last_cmd = cmd;
				++mon_cmds;
			}
		}

		ServiceRfid();

		/* The ESP32's BP prediction, taken ONCE per pass and cached in the mon_
		 * globals, which is what makes the LoRa packet and the I2C snapshot agree.
		 *
		 * tb_slave_take_bp() consumes the fresh flag, so calling it from both
		 * publish sites would give whichever ran first the reading and the other
		 * nothing. Taking here instead -- before PublishToEsp32(), so a pair that
		 * arrived this pass is in the very next snapshot, and before any
		 * PackTelemetry() the next poll triggers -- means the take happens in one
		 * place and everything downstream reads state.
		 *
		 * Sticky on purpose: nothing clears mon_bp_* on a quiet pass. The flag
		 * says "new", the variables say "last known", and only a new validated
		 * write moves them; a rejected pair does not reach here at all. */
		{
			uint16_t sys;
			uint16_t dia;
			if (tb_slave_take_bp(&sys, &dia)) {
				mon_bp_sys = sys;
				mon_bp_dia = dia;
				mon_bp_valid = 1U;
				++mon_bp_updates;
			}
		}

		PublishToEsp32();

		{
			uint8_t prio;
			uint8_t conf;
			uint8_t esi;
			if (tb_slave_take_result(&prio, &conf, &esi)) {
				/* Straight onto the LoRa packet: the wire numbering here and at
				 * TB_REG_PRIORITY are the same LoRa alias, so this is a copy and
				 * not a conversion. Sticky until the ESP32 scores again, which
				 * is what the station wants -- a vital arriving between scores
				 * should carry the standing triage level, not drop back to
				 * unscored. The ESI travels with them by construction: the slave
				 * latched it in the same store as the confidence byte, so the
				 * score and the colour can only ever come from one model run. */
				mon_priority = prio;
				mon_confidence = conf;
				mon_esi = esi;
			}
		}

		HAL_Delay(10);
	}
  /* USER CODE END 3 */
}

void SystemClock_Config(void)
{
  RCC_OscInitTypeDef RCC_OscInitStruct = {0};
  RCC_ClkInitTypeDef RCC_ClkInitStruct = {0};

  /** Configure the main internal regulator output voltage
  */
  __HAL_RCC_PWR_CLK_ENABLE();
  __HAL_PWR_VOLTAGESCALING_CONFIG(PWR_REGULATOR_VOLTAGE_SCALE1);

  /** Initializes the RCC Oscillators according to the specified parameters
  * in the RCC_OscInitTypeDef structure.
  */
  RCC_OscInitStruct.OscillatorType = RCC_OSCILLATORTYPE_HSE;
  RCC_OscInitStruct.HSEState = RCC_HSE_ON;
  RCC_OscInitStruct.PLL.PLLState = RCC_PLL_ON;
  RCC_OscInitStruct.PLL.PLLSource = RCC_PLLSOURCE_HSE;
  RCC_OscInitStruct.PLL.PLLM = 12;
  RCC_OscInitStruct.PLL.PLLN = 96;
  RCC_OscInitStruct.PLL.PLLP = RCC_PLLP_DIV2;
  RCC_OscInitStruct.PLL.PLLQ = 5;
  if (HAL_RCC_OscConfig(&RCC_OscInitStruct) != HAL_OK)
  {
    Error_Handler();
  }

  /** Initializes the CPU, AHB and APB buses clocks
  */
  RCC_ClkInitStruct.ClockType = RCC_CLOCKTYPE_HCLK|RCC_CLOCKTYPE_SYSCLK
                              |RCC_CLOCKTYPE_PCLK1|RCC_CLOCKTYPE_PCLK2;
  RCC_ClkInitStruct.SYSCLKSource = RCC_SYSCLKSOURCE_PLLCLK;
  RCC_ClkInitStruct.AHBCLKDivider = RCC_SYSCLK_DIV1;
  RCC_ClkInitStruct.APB1CLKDivider = RCC_HCLK_DIV2;
  RCC_ClkInitStruct.APB2CLKDivider = RCC_HCLK_DIV1;

  if (HAL_RCC_ClockConfig(&RCC_ClkInitStruct, FLASH_LATENCY_3) != HAL_OK)
  {
    Error_Handler();
  }
}

/* USER CODE BEGIN 4 */
/* HAL_TIM_PeriodElapsedCallback is gone. It existed only to set lora_send_ready
 * for the free-running transmit, so with polling there is nothing for TIM10 to
 * do and HAL_TIM_Base_Start_IT(&htim10) is no longer called. MX_TIM10_Init() is
 * left in place because CubeMX regenerates it from the .ioc; the timer is
 * configured and simply never started, which costs nothing. Removing it properly
 * means deleting TIM10 in the .ioc, and TIM2 (the ADC trigger) must not be
 * touched while doing so.
 *
 * If TIM10 is ever wanted again, note that its configured period is 75ms
 * (prescaler 999, period 7500 on a 100MHz APB2 timer clock), not the 750ms the
 * deleted NODE_REPORT_INTERVAL claimed -- the two never agreed. */

void HAL_ADC_ConvCpltCallback(ADC_HandleTypeDef *hadc) {
	// if (hadc->Instance != ADC1) return; Commented, no other ADC
	(void) hadc;

	uint16_t ecg_sample = analog_data[ECG_ADC_INDEX];
	uint16_t mic_sample = analog_data[MIC_ADC_INDEX];
	mon_ecg_raw = ecg_sample;
	mon_mic_raw = mic_sample;
	++mon_adc_samples;

	/* ---- ECG: fill the current bank, hand it over when full ---- */
	uint8_t bank = ecg_fill_bank;
	ecg_buffer[bank][ecg_buffer_index++] = ecg_sample;

	if (ecg_buffer_index >= ECG_BUFFER_SIZE) {
		ecg_buffer_index = 0;
		/* Only hand over if the main loop has released the previous window;
		 * otherwise keep overwriting this bank rather than corrupting the one
		 * being processed. */
		if (ecg_ready_bank == 0xFF) {
			ecg_ready_bank = bank;
			ecg_fill_bank = (uint8_t) (bank ^ 1U);
		}
	}

	/* ---- ECG for the ESP32: 5-sample boxcar, staged for the waveform ring ----
	 *
	 * The waveform block carries one ECG value per PPG sample, and the two
	 * sources run at different rates: this ADC at DSP_ADC_FS_TRUE_HZ = 500 Hz
	 * (TIM2: 100 MHz / 1000 / 200), the MAX30102 at DSP_PPG_FS_HZ = 100 Hz. Five
	 * raw samples per staged value brings the ECG to exactly 100 Hz.
	 *
	 * A boxcar rather than a decimating pick-one-in-five, because dropping four
	 * samples out of five folds everything above the new 50 Hz Nyquist back
	 * down, and the bands that land on the 5-30 Hz QRS -- 70-95 Hz, 105-130 Hz,
	 * 170-195 Hz -- are exactly where the AD8232's broadband noise sits. The
	 * 5-tap mean nulls at 100 Hz and its multiples and holds those bands at least
	 * 8 dB down, 25 dB and better through their middles: a cheap partial
	 * anti-alias rather than a brick wall, which is the right trade for four adds
	 * in an ISR. The 50 Hz mains line is only 3.8 dB down and does not need to be:
	 * it lands exactly on the new Nyquist, still clear of the QRS band. None of
	 * this touches the STM32's own ECG path -- that one keeps the full 500 Hz
	 * stream in ecg_buffer above.
	 */
	{
		static uint32_t ecg_box_sum = 0;
		static uint8_t ecg_box_n = 0;

		ecg_box_sum += ecg_sample;
		if (++ecg_box_n >= ECG_WAVE_DECIM) {
			/* A divide, not the shift a power-of-two window would allow: /4
			 * would leave a 1.25x gain on a field documented as raw ADC counts,
			 * and the ESP32 would scale the R wave it measures amplitudes from.
			 * UDIV is a handful of cycles on Cortex-M4, once per 5 samples at
			 * 500 Hz, i.e. under 0.01% of the ISR budget. */
			mon_ecg_staged = (uint16_t) ((ecg_box_sum + (ECG_WAVE_DECIM / 2U))
					/ ECG_WAVE_DECIM);
			mon_ecg_staged_valid = 1U;
			ecg_box_sum = 0U;
			ecg_box_n = 0U;
		}
	}

	/* ---- Respiratory: mic sample into the envelope detector ---- */
	Dsp_MicPushSample(mic_sample);
}

/* HAL calls HAL_GPIO_EXTI_Callback (no line number in the name) from
 * HAL_GPIO_EXTI_IRQHandler. The old HAL_GPIO_EXTI9_5_Callback was never
 * called by anything, which is why the MAX30102 needed a polling fallback.
 *
 * Only the MAX30102 is handled here. SX1278_DIO0 (PB1) is configured as an
 * EXTI line in gpio.c but nothing services it, and that stays true now that the
 * node receives as well as transmits: EXTI1_IRQn is not enabled in the NVIC, and
 * ServiceLoRaPoll() reads DIO0 as a level rather than waiting for the edge. The
 * flag latches until the flags register is cleared, so polling it loses nothing,
 * and an ISR that fired on an unattended edge would only have to set a variable
 * the superloop already computes. LoRa_transmit() likewise polls RegIrqFlags for
 * TxDone and clears them itself. */
void HAL_GPIO_EXTI_Callback(uint16_t GPIO_Pin) {
	if (GPIO_Pin == MAX30102_INT_Pin) {
		max30102_on_interrupt(&hmax30102);
	}
}

/* Called by the MAX30102 driver for every FIFO sample it reads.
 *
 * The driver's parameter names are not trustworthy. Per the MAX30102 register
 * map, 0x0C is LED1_PA = RED and 0x0D is LED2_PA = IR, and in SpO2 mode the
 * FIFO word order is LED1 (RED) first, then LED2 (IR). This driver has those
 * labels the other way round: it #defines MAX30102_LED_IR_PA1 as 0x0c and
 * unpacks FIFO bytes [0..2] as "ir". So what arrives here as ir_sample is
 * physically the RED channel and vice versa.
 *
 * Left uncorrected this inverts the ratio-of-ratios: instead of R ~ 0.5 for a
 * healthy finger you get R ~ 1.9, which fails the 70% floor and reports
 * DSP_SPO2_REJ_SPO2_LOW (reject code 5). Swapped here, at the one and only
 * place the driver's labels cross into application code.
 *
 * MON_SPO2_SWAP_CHANNELS exists because the above rests on the datasheet
 * register map rather than on a measurement of THIS board. It has now been tried
 * both ways on hardware and the swap stays ON -- but read the next paragraph
 * before flipping it, because the obvious check is the misleading one.
 *
 * The tempting test is mon_spo2_ir_dc > mon_spo2_red_dc, on the grounds that
 * tissue attenuates 660nm far more than 880nm. That test HAS A PRECONDITION:
 * the light must have gone through tissue. Used with an air gap, a large
 * wavelength-flat shunt -- reflection off the package and the skin surface,
 * never entering the finger -- dominates DC, so which channel reads larger is
 * then set by LED-to-photodiode geometry (the two dies are not equidistant from
 * the detector) rather than by haemoglobin. Measured 2026-08-22: the two DC
 * values sat only 1.14x apart, 160k against 140k, either way round. That
 * compression is the shunt, and it is why the DC test cannot arbitrate here.
 *
 * R is what arbitrates, because AC can only come from pulsating blood. R is
 * exactly reciprocal between the two settings, so one of them is always
 * physiological and the other always absurd. Swap OFF gave R ~1.5 on a healthy
 * finger: 70-75%, flickering to DSP_SPO2_REJ_SPO2_LOW whenever R crossed 1.6.
 * Swap ON is the reciprocal, R ~0.65 -> ~94%. Expect 0.4-0.9 on a healthy
 * subject; R > 1 is either real severe hypoxia or this macro being wrong, and on
 * someone walking and talking it is this macro.
 *
 * Whichever way it is set, perfusion (ir_ac/ir_dc) is computed on whatever this
 * call labels IR. Backwards, it is measured on the physically-red channel, which
 * carries the smaller AC -- so perfusion reads low and unstable while the
 * percentage can still look plausible. */
#define MON_SPO2_SWAP_CHANNELS 1

/* The wire block declares the waveform's sample rate so the ESP32 can put a
 * time axis on it. This is the only place both constants are visible, so it is
 * the only place the duplication can be caught. */
_Static_assert(TB_PPG_FS_HZ == DSP_PPG_FS_HZ,
		"tb_regs.h TB_PPG_FS_HZ must track dsp_utils.h DSP_PPG_FS_HZ");

/* The ECG channel in that block is staged by the boxcar in
 * HAL_ADC_ConvCpltCallback, which divides the ADC rate by ECG_WAVE_DECIM. The
 * result has to equal the PPG rate the block declares, or the ESP32 is putting
 * two different time axes on one sample slot. Equality since TIM2 ARR became 199
 * (500 / 5 = 100); it was a 5% range while the ADC ran at 497.5 Hz. */
_Static_assert(DSP_ADC_FS_HZ == ECG_WAVE_DECIM * TB_PPG_FS_HZ,
		"the ECG boxcar no longer lands on TB_PPG_FS_HZ");

/* And the block has to be reachable at all. The I2C register pointer is one
 * byte, so a ring size or a base that pushes the tail past 0xFF makes the last
 * samples silently unreadable -- the slave clamps the length and the ESP32 parses
 * a short read as a complete one. tb_link_selftest.c pins this too; it is here as
 * well so the firmware build fails on it without a host toolchain, since the ring
 * size is now dictated by exactly this ceiling. */
_Static_assert(TB_REG_PPG_END <= 0x100U,
		"the waveform block runs past the one-byte register pointer");
_Static_assert(sizeof(tb_wave_block_t) == (TB_REG_PPG_END - TB_REG_PPG_BASE),
		"tb_wave_block_t and TB_REG_PPG_END disagree about the block size");

void max30102_plot(uint32_t ir_sample, uint32_t red_sample) {
#if MON_SPO2_SWAP_CHANNELS
	uint32_t ir = red_sample;
	uint32_t red = ir_sample;
#else
	uint32_t ir = ir_sample;
	uint32_t red = red_sample;
#endif
	mon_ir_raw = ir;
	mon_red_raw = red;

	Dsp_PpgSample smooth;
	Dsp_Spo2PushSample(ir, red, &smooth);
	mon_ppg_ir_smooth = smooth.ir;
	mon_ppg_red_smooth = smooth.red;
	mon_ppg_pulse = smooth.pulse;
	mon_ppg_norm_pct = smooth.norm_pct;

	/* Skin contact, from the SAME floor the SpO2 DC gate uses, so the waveform
	 * and the percentage can never disagree about whether a finger is present.
	 *
	 * Taken from the smoothed RED rather than the raw sample for two reasons:
	 * RED is the smaller channel (tissue attenuates it far more than infrared),
	 * so it is the one that trips first; and the 10Hz FIR means a single noisy
	 * sample cannot toggle the bit. The cost is the filter's 150ms group delay,
	 * which is 15 samples of lag on a decision a human makes in a second.
	 *
	 * Note this responds in ~150ms while the SpO2 percentage takes a 1.28s
	 * block, so the ESP32 sees contact drop before the number does. That order
	 * is deliberate: the screen stops trusting the waveform first. */
	mon_ppg_contact = (smooth.red >= DSP_PPG_MIN_DC) ? 1U : 0U;

	/* Hand the smoothed waveform to the ESP32, which does its own PPG
	 * processing and runs the BP model on it. Both PPG channels in raw counts,
	 * already swapped above, so what the ESP32 calls IR is physically IR -- the
	 * driver's label confusion stops here and never crosses the link. The ring
	 * absorbs the gap between this 100Hz push and however often the ESP32 gets
	 * round to reading it; see tb_regs.h for what it must do with the sample
	 * counter.
	 *
	 * The ECG rides along as the LATEST staged value rather than one carried in
	 * from the sample instant, because the two sensors have no shared clock: the
	 * MAX30102 announces a sample over I2C1 whenever its FIFO says so, and the
	 * ADC stages one every 10.05 ms from TIM2. So the pair is "the newest ECG at
	 * the moment this PPG sample arrived", which is what the block's one-counter
	 * layout can express.
	 *
	 * ponytail: that gives up to one staging period, ~10 ms, of pairing skew,
	 * uniformly distributed, so ±5 ms about the mean. It is the largest single
	 * error in a pulse transit time and it is deliberately left: PTT features are
	 * means over several beats, and a zero-mean jitter averages down as
	 * 5/sqrt(beats) ms -- under 2 ms across an 8-beat window, which is inside the
	 * model's own input noise. Upgrade path if it turns out to matter: timestamp
	 * both sources off HAL_GetTick (or a free-running TIM) and interpolate the ECG
	 * to the PPG instant, which needs a second field in the sample or a shared
	 * time base on the wire. Before doing that, check the MAX30102's own FIFO
	 * latency -- smp_ave_8 at sr_800 is itself a 10 ms group delay, so the ECG is
	 * not the biggest unknown in the pairing.
	 *
	 * Zero until the boxcar has its first five samples, which is 10 ms after the
	 * ADC starts and long before the MAX30102's first FIFO word. Pushed
	 * unconditionally: mon_ecg_staged_valid is the diagnostic that distinguishes
	 * "nothing staged yet" from a measured 0, and 0 counts is what an unplugged
	 * AD8232 reads anyway, so gating the push would only cost the ESP32 the PPG
	 * samples in the same slot. */
	tb_slave_wave_push(smooth.ir, smooth.red, mon_ecg_staged);
}

/* Builds the LoRa uplink packet from the mon_* globals, immediately before the
 * transmit, so one frame always carries one self-consistent set of readings.
 *
 * Reads the globals for the same reason PublishToEsp32 does: they are already
 * the one place every produced value lands. The fields used to be assigned at
 * each computation site instead, which meant every vital existed twice -- once
 * for the ESP32 and once for the radio -- and the two could drift apart with no
 * symptom on either link. The only per-link difference left is respiratory rate,
 * which the I2C map carries in tenths and the MQTT vital wants whole. */
/* Respiratory rate is OFF at the source until the microphone physically exists.
 * Set to 1 when the PCB carrying the 3.5 mm mic jack is built, then calibrate the
 * signal-strength gate this replaces (see below).
 *
 * PA2 is an unconnected pin today and the respiratory path cannot tell. Measured
 * with no mic fitted: the FFT's five strongest peaks came back 16.8, 16.0, 14.2,
 * 10.5 and 9.7 -- the "strongest" component is 1.05x the runner-up, which is
 * exactly what a flat noise floor looks like -- and mon_resp_peak_ratio only
 * reached 2.76-3.23. Yet mon_resp_brpm published 12-13 brpm on some windows and
 * lit both TB_FLAG_RR_VALID and TB_SENSOR_MIC.
 *
 * A peak-prominence gate is the eventual fix, and it is deliberately NOT here yet:
 * the reject side is measurable (noise stays under 3.3) but the accept side is not,
 * because there is no mic to breathe into. A guessed threshold set too high would
 * leave RR permanently silent once the mic arrives, with nothing to point at.
 *
 * Off rather than gated, because of what this number means to whoever reads it.
 * 13 brpm reads as normal respiration on a casualty who may not be breathing at
 * all. A blank column is a visible failure an operator retries; a plausible wrong
 * number is not. The DSP keeps running either way, so mon_resp_* stays available
 * over SWD for the calibration session. */
#define MON_RESP_MIC_FITTED 0

/* Respiratory rate as it goes on both wires: the measurement when a mic exists,
 * a hard 0 ("no reading", per tb_regs.h) when one does not. One accessor so the
 * I2C block and the LoRa packet cannot disagree. */
/*
 * Drop everything that belongs to one patient.
 *
 * Every field here is sticky by design, and each reason is good on its own: a
 * vital sent between two scores should carry the standing verdict rather than
 * report "unscored", and the same for the predicted pressure. What was missing is
 * the event that ends the stickiness. Without it the last patient's verdict stands
 * until power-off, and since the station publishes a vital for exactly as long as a
 * verdict stands, the node keeps reporting a patient who has gone -- every 15 s,
 * with every measurement blank because nobody is on the sensors. Those blanks are
 * the newest readings the backend holds, so they bury the real measurement.
 *
 * Called on START_SCAN (a new patient inherits nothing) and on ABORT (the operator
 * returned to Home, so this node has no patient). Not from POWER_OFF: the rail is
 * about to drop and a last honest packet is better than a blanked one.
 *
 * The tag goes too, which is what stops a scanning screen from "succeeding"
 * instantly on the previous card -- the failure that attaches one patient's
 * telemetry to another's identity.
 *
 * mon_confidence follows mon_priority rather than being left alone: a confidence
 * for a verdict that no longer exists describes nothing, and the station emits the
 * pair together.
 */
static void ForgetPatient(void) {
	rfid_ascii_len = 0U;
	mon_priority = LORA_VITAL_PRIORITY_NONE;
	mon_confidence = 0U;
	mon_esi = LORA_VITAL_ESI_NONE; /* with the verdict it was scored in, see it */
	/* Cleared, not just marked invalid: TB_FLAG_BP_VALID gates whether the pair
	 * is published, but a stale 120/80 sitting in a debugger or an i2creg dump
	 * next to a fresh patient is its own way to mislead. */
	mon_bp_valid = 0U;
	mon_bp_sys = 0U;
	mon_bp_dia = 0U;
}

static float ResolvedRespBrpm(void) {
#if MON_RESP_MIC_FITTED
	return mon_resp_brpm;
#else
	return 0.0f;
#endif
}

/*
 * The respiratory rate that goes on the LoRa wire and lights TB_FLAG_RR_VALID:
 * the microphone's measurement when a microphone exists, the operator's typed
 * value from TB_REG_HOST_RR otherwise, 0 if neither. WHOLE breaths/min, which is
 * the unit both the packet and the MQTT vital use.
 *
 * This exists because the wire was disagreeing with the decision it carried. The
 * ESP32's tb_classify() REFUSES to score on respiratory_rate <= 0, so every
 * verdict this node has ever transmitted was computed from the typed value --
 * while the packet reported no rr at all and the station omitted the key. The
 * flag is the honest version of that: "this is the RR the verdict came from",
 * which is all the JSON can express.
 *
 * NOT echoed into TB_REG_RR_X10, deliberately. That register stays the
 * microphone's field and stays 0, so the ESP32's own poll cannot read an
 * operator's estimate back as a measurement and present it with sensor
 * provenance. The read-block echo that HOST_BATTERY gets is right for a gauge
 * and wrong for a human's guess.
 *
 * The clamp only guards a future change to the estimator's search range -- it is
 * bounded well under 255 today -- but the field is one byte, so 255 has to mean
 * something rather than wrap to 0.
 */
static uint8_t WireRespBrpm(void) {
	float mic = ResolvedRespBrpm();

	if (mic > 254.0f) {
		return 255U;
	}
	if (mic > 0.0f) {
		return (uint8_t) (mic + 0.5f);
	}
	return tb_slave_host_rr(); /* 0 when the ESP32 has none either */
}

static void PackTelemetry(void) {
	float spo2 = mon_spo2_pct;
	uint8_t len = rfid_ascii_len;

	mon_lora_vital.node_id = mon_node_id;
	mon_lora_vital.version = LORA_VITAL_VERSION;
	++mon_lora_vital.packet_counter; /* wraps; the station diffs for loss */
	mon_lora_vital.flags = mon_flags;
	mon_lora_vital.device_status = mon_sensor_ok;

	/* mon_rate_bpm, not mon_hr_bpm: the ECG rate when there is one, the PPG pulse
	 * rate otherwise. mon_flags carries TB_FLAG_HR_FROM_PPG so the station can
	 * see which, and the field itself stays "hr" so the MQTT contract does not
	 * move. */
	mon_lora_vital.hr = mon_rate_bpm;
	mon_lora_vital.spo2 = (uint8_t) ((spo2 > 100.0f) ? 100U :
										(spo2 > 0.0f) ? (uint8_t) (spo2 + 0.5f) : 0U);
	/* Whole breaths/min: the mic when one exists, else the operator's typed
	 * value -- WireRespBrpm() owns that choice and its comment owns the why. */
	mon_lora_vital.rr = WireRespBrpm();
	/* The ESP32's ML prediction, arriving at TB_REG_HOST_BP_SYS/DIA and taken
	 * once per superloop pass into these globals -- see the take site. mon_flags
	 * carries TB_FLAG_BP_VALID from the same pair, so the station never sees a
	 * pressure without the bit or a bit without a pressure. 0/0 with the bit
	 * clear until the model has spoken, which is what makes the station omit the
	 * keys rather than publish a fabricated 0/0. */
	mon_lora_vital.bp_sys = mon_bp_sys;
	mon_lora_vital.bp_dia = mon_bp_dia;
	/* The gauge is the ESP32's SW6106 PMIC, not ours -- it arrives over I2C at
	 * TB_REG_HOST_BATTERY. 0xFF when it has not sent one yet, which is exactly
	 * LORA_VITAL_BATTERY_NONE, so the station omits the key as before. */
	mon_lora_vital.battery = tb_slave_host_battery();

	/* Whatever the ESP32 last decided, or NONE if it has not decided yet. */
	mon_lora_vital.priority = mon_priority;
	mon_lora_vital.confidence = mon_confidence;
	/* The model's raw 1..5, which the colour cannot carry: tb_classify() collapses
	 * ESI 3, 4 and 5 all into GREEN, so a walking-wounded 5 and a
	 * could-deteriorate 3 are indistinguishable by the time they reach here. Taken
	 * with the verdict, not as state, so it can never belong to a different model
	 * run than the colour beside it. 0 = unscored, which is the same condition
	 * that makes priority NONE, so the station is already withholding the vital. */
	mon_lora_vital.esi = mon_esi;
	/* The two facts only the operator can supply, straight from the write block.
	 * Age is in YEARS -- the clinical mid-point of the band the model scored, not
	 * the band index -- so the station reports the input the verdict came from.
	 * Gender goes through the helper rather than a cast: 'M'/'F' pass, and
	 * anything else (including the UI's 'U') becomes 0 so the station omits the
	 * key instead of publishing an unknown as an answer. */
	mon_lora_vital.age = tb_slave_host_age();
	mon_lora_vital.gender = lora_vital_gender_byte((char) tb_slave_host_gender());

	/* The tag as published to the ESP32, so both links name the same patient.
	 * Clamped rather than trusted: rfid_ascii holds TB_RFID_MAX (31) and this
	 * field is LORA_VITAL_RFID_MAX (20), and the static assert below only proves
	 * the current source cannot exceed it. */
	if (len > LORA_VITAL_RFID_MAX) {
		len = LORA_VITAL_RFID_MAX;
	}
	mon_lora_vital.victim_rfid_len = len;
	memset(mon_lora_vital.victim_rfid, 0, sizeof(mon_lora_vital.victim_rfid));
	memcpy(mon_lora_vital.victim_rfid, rfid_ascii, len);
}

/* ---- Node identity: the UID -> node_id table ----------------------------- */
/*
 * The station polls addresses 1..LORA_POLL_NODE_MAX, so node_id cannot be
 * derived from the 96-bit factory UID -- it has to be ASSIGNED, and this table is
 * where. One binary for the whole fleet, looked up at boot; no per-board build
 * configuration, because that is the step mass production skips.
 *
 * TO ADD A BOARD: connect its ESP32 and run the `uid` console command, which
 * prints this chip's twelve bytes straight off the I2C link (TB_REG_UID). Paste
 * them in that order, pick the next free id in 1..LORA_POLL_NODE_MAX, reflash.
 * A serial monitor is the whole toolchain -- no debugger, no SWD probe.
 *
 * A UID THAT IS NOT IN THE TABLE RESOLVES TO 0, and 0 means this board keeps its
 * mouth shut: lora_poll_for_me() never matches a 0 id, so it answers no poll,
 * TB_SENSOR_LORA stays clear so the ESP32's own status dot shows it, and
 * mon_node_id is the variable to read over SWD when a freshly flashed board never
 * appears on the dashboard. The asymmetry is the point -- a silent board is a
 * one-line diagnosis, while a second board answering as node 1 merges two
 * patients into one MQTT record and looks like working telemetry.
 */
static const struct node_uid {
	uint8_t uid[TB_REG_UID_LEN]; /**< as the ESP32's `uid` command prints it */
	uint8_t id;                  /**< poll address, 1..LORA_POLL_NODE_MAX */
} k_node_uids[] = {
	/* One row per board, in this shape:
	 *   { { 0xXX, 0xXX, 0xXX, 0xXX, 0xXX, 0xXX, 0xXX, 0xXX, 0xXX, 0xXX, 0xXX, 0xXX }, 1U },
	 * The row is commented out rather than filled with a guess: an invented UID
	 * committed here would hand a real board somebody else's identity, which is
	 * the exact failure the table exists to end. */
	/* { { 0xXX, 0xXX, 0xXX, 0xXX, 0xXX, 0xXX, 0xXX, 0xXX, 0xXX, 0xXX, 0xXX, 0xXX }, 1U }, */
	{ { 0U }, 0U }, /* C has no empty initialiser, and this row can only ever
	                 * resolve to "no address": an all-zero UID is not a chip ST
	                 * makes, and id 0 is the reserved address. A deliberate no-op
	                 * -- replace it with the fleet, do not keep it under them. */
};

/*
 * This board's address: its table entry if the UID is known, else the -DNODE_ID
 * it was built with, else 0 for "no address" (see the table).
 *
 * THE TABLE WINS over the override, deliberately. A -DNODE_ID left behind in
 * somebody's build configuration must not be able to move a board the table
 * already names, because the table is what the fleet's records are keyed on. The
 * override exists for the board that is not in the table yet, and for that only.
 *
 * The bound is the runtime half of what _Static_assert(NODE_ID ...) used to do,
 * and it is needed for the same two silent failures: id 0 would answer every
 * node's poll, and an id above the maximum is never polled at all, which is
 * indistinguishable from a dead radio.
 *
 * The table arrives as an argument rather than being read from the global it
 * always is at runtime, which is what makes the lookup host-testable at all: the
 * shipped table cannot contain an invented UID, so a hit on a real address can
 * only be exercised with one the test supplies. See tools/lora_poll_selftest.c.
 */
static uint8_t NodeIdFromUid(const uint8_t *uid, const struct node_uid *tab,
		size_t n) {
	uint8_t id = (uint8_t) NODE_ID; /* 0 unless the build line said otherwise */
	size_t i;

	for (i = 0U; i < n; ++i) {
		if (memcmp(uid, tab[i].uid, TB_REG_UID_LEN) == 0) {
			id = tab[i].id;
			break;
		}
	}
	if (id > LORA_POLL_NODE_MAX) {
		id = 0U; /* a mis-typed table row fails the same way an unknown UID does */
	}
	return id;
}

/*
 * The poll address chosen in the ESP32's Menu wins over the UID table and over
 * -DNODE_ID: it is the operator's explicit, current choice, and the ESP32
 * re-sends it every few seconds from its own persistent store, so a board that
 * reset comes back on the same address without anyone touching it.
 *
 * An out-of-range byte (0 = never written, or above the maximum) is IGNORED and
 * the current address kept: applying it would turn one bad byte into a node that
 * is never polled, which looks exactly like a dead radio. Changing the address
 * while a reply is in flight is harmless -- mon_node_id is one byte, read once
 * per poll and once per packet build.
 */
static uint8_t ResolveHostNodeId(uint8_t host, uint8_t current) {
	return ((host >= 1U) && (host <= LORA_POLL_NODE_MAX)) ? host : current;
}
/* ---- end of the host-testable node identity ---- */

/* Resolve this board's address from its own UID, once, at boot. UID_BASE is a
 * read-only factory register, so there is nothing to re-read later.
 *
 * These are the same twelve bytes, read the same way, that tb_slave_init()
 * published at TB_REG_UID -- which is the invariant the whole scheme rests on:
 * what the ESP32's `uid` command prints has to be what this lookup matches, or
 * a UID pasted into the table would never hit. Both sides are a memcpy from
 * UID_BASE for exactly that reason; neither may reorder the bytes. */
static void ResolveNodeId(void) {
	uint8_t uid[TB_REG_UID_LEN];

	memcpy(uid, (const void *) UID_BASE, sizeof(uid));
	mon_node_id = NodeIdFromUid(uid, k_node_uids,
			sizeof(k_node_uids) / sizeof(k_node_uids[0]));
}

/* One superloop pass of the LoRa slave side: notice a completed reception and,
 * if it was a poll addressed to this node, answer it with a fresh snapshot.
 *
 * This replaced a 750ms free-running transmit on 2026-08-18. Nodes now never
 * speak first -- see Core/Inc/lora_poll.h for why, and docs/lora-air-protocol.md
 * for the station's half. Nothing else in this firmware may call LoRa_transmit.
 *
 * Cost when the radio is idle, which is 99.9% of passes: one GPIO read. */
_Static_assert(LORA_REPLY_DEADLINE_MS + LORA_REPLY_AIRTIME_MS
		< LORA_POLL_SLOT_MS,
		"a reply could still be in the air when the station's slot ends");
_Static_assert(LORA_TX_TIMEOUT > LORA_REPLY_AIRTIME_MS
		&& LORA_TX_TIMEOUT < LORA_POLL_SLOT_MS,
		"LORA_TX_TIMEOUT must outlast a good transmit and give up inside the slot");

static void ServiceLoRaPoll(void) {
	/* Tick at the previous check. The poll's age is bounded by now - this,
	 * because DIO0 was low the last time we looked.
	 *
	 * primed exists because the first pass has no previous check: last_check_ms
	 * would be 0 against a tick already past 1s of sensor init, so a poll that
	 * latched during that init would be discarded as stale and mon_lora_stale
	 * would sit at 1 forever, reading as a latency problem that is not there. */
	static uint32_t last_check_ms;
	static uint8_t primed;
	uint8_t rx[LORA_POLL_LEN];
	uint32_t now;
	uint32_t age;
	uint8_t irq;
	uint8_t n;

	if (lora_status != LORA_OK) {
		return;
	}

	now = HAL_GetTick();
	age = primed ? (now - last_check_ms) : 0U; /* wrap-safe subtraction */
	last_check_ms = now;
	primed = 1U;

	/*
	 * DIO0 as a LEVEL, and the only thing touched while the radio is idle.
	 *
	 * Calling LoRa_receive() speculatively would be a bug rather than a
	 * waste: it drops the modem to standby to inspect the flags, which ABORTS
	 * a reception already in progress. A ~10ms superloop against a ~30ms poll
	 * frame would abort almost every poll mid-air, and the link would look
	 * dead while both radios were configured perfectly.
	 *
	 * DIO0 is RxDone here: LoRa_init() ORs RegDioMapping1 with 0x3F, leaving
	 * bits 7:6 (DIO0) at the reset value 00, which is RxDone in the RX modes.
	 * A high level therefore means a whole packet is already in the FIFO and
	 * talking to the chip now cannot interrupt anything. EXTI1 is not enabled
	 * in the NVIC, so this is polled -- which is sufficient because the flag
	 * latches until something clears it, unlike the edge.
	 */
	if (HAL_GPIO_ReadPin(hlora.DIO0_port, hlora.DIO0_pin) != GPIO_PIN_SET) {
		return;
	}

	irq = LoRa_read(&hlora, RegIrqFlags);
	if ((irq & LORA_IRQ_CRC_ERROR) != 0U) {
		/* Somebody transmitted and the link is marginal -- a different
		 * fault from silence, and the only one antenna work fixes. The
		 * library ignores this flag, so without this test a corrupt frame
		 * would be parsed as a poll. Clearing the flags drops DIO0 and
		 * leaves the radio in RX continuous; the unread payload is
		 * overwritten by the next packet, so there is nothing to drain. */
		LoRa_write(&hlora, RegIrqFlags, 0xFFU);
		++mon_lora_crc;
		return;
	}

	/* Five bytes is the whole poll, and reading no more is deliberate: a
	 * longer frame is another node's reply on this shared channel, and byte 0
	 * of a vital is the sender's node_id, which is never LORA_POLL_MAGIC. So
	 * lora_poll_for_me() rejects it on the first byte and the rest of the
	 * frame never has to be copied anywhere. */
	n = LoRa_receive(&hlora, rx, sizeof(rx));
	if (n == 0U) {
		/* DIO0 was high for something that was not RxDone, so LoRa_receive()
		 * left the flags alone. Clear them anyway: an IRQ flag nothing ever
		 * clears holds DIO0 high forever and this function would then talk
		 * to the radio on every single pass, which is not a hang but is a
		 * permanent cost for no packets. Nothing is lost -- RxDone is
		 * provably clear here. */
		LoRa_write(&hlora, RegIrqFlags, 0xFFU);
		return;
	}
	++mon_lora_rx;

	/* Not logged and not counted separately: on a 20-node channel, hearing
	 * traffic that is not ours is the common case, not an anomaly. A version
	 * mismatch lands here too -- acting on a packet this node cannot parse is
	 * worse than dropping it. */
	if (!lora_poll_for_me((const lora_poll_t *) rx, n, mon_node_id)) {
		return;
	}

	/* Unknown commands are ignored SILENTLY. A NAK from every node at once is
	 * itself a collision, and the command byte exists precisely so the station
	 * can gain commands without reflashing every node in the field. */
	if (((const lora_poll_t *) rx)->command != LORA_POLL_CMD_REPORT) {
		return;
	}
	++mon_lora_polls;

	/*
	 * RSSI of THIS packet, latched now: the poll is confirmed to be from the
	 * station, so the level means something. It goes to the ESP32 over I2C for
	 * its status bar -- the only link-quality figure this node can know, since
	 * it never transmits unpolled and so only ever measures the downlink.
	 *
	 * BEFORE the reply, deliberately. RegPktRssiValue is per-packet, and
	 * LoRa_transmit() returns the radio to RX continuous, where the next thing
	 * heard is very likely another node answering its own poll on this shared
	 * channel -- which would overwrite the register with that node's level.
	 *
	 * The clamp is load-bearing, not defensive. LoRa_getRSSI() returns
	 * -164 + RegPktRssiValue, so its range is -164..+91, and -164 narrowed to
	 * int8_t wraps to +92: a value that passes every plausibility test and
	 * displays as an extremely strong signal. Clamping to int8_t's range keeps
	 * the out-of-band values ABOVE the strongest real signal, where
	 * tb_rssi_valid() rejects them.
	 */
	{
		int rssi = LoRa_getRSSI(&hlora);

		/* Raw first, so CubeMonitor shows what the radio actually reported --
		 * a reading pinned at -128 hides whether the register read is broken
		 * (0 -> -164) or the signal is genuinely at the floor. */
		mon_lora_rssi = (int16_t) rssi;

		if (rssi < -128) {
			rssi = -128;
		} else if (rssi > 127) {
			rssi = 127;
		}
		tb_slave_set_rssi((int8_t) rssi);
	}

	if (age > LORA_REPLY_DEADLINE_MS) {
		/* Deliberately silent on the radio: see LORA_REPLY_DEADLINE_MS.
		 * The station counts a miss, three misses publish this node
		 * OFFLINE, and mon_lora_stale is the only place that says the
		 * cause was this node's own latency rather than a dead link. */
		++mon_lora_stale;
		return;
	}

	/* Snapshot now, not on a timer: the reply must carry the newest reading,
	 * and PackTelemetry() reads the same mon_* globals the ESP32 link
	 * publishes, so both links describe the same patient at the same instant.
	 *
	 * LoRa_transmit() restores the mode it was called in, so the radio returns
	 * to RX continuous by itself -- no LoRa_startReceiving() needed here. A
	 * timeout return (0) leaves mon_lora_frames behind mon_lora_polls, which is
	 * the signal documented with the counters above. */
	PackTelemetry();
	if (LoRa_transmit(&hlora, (uint8_t *) &mon_lora_vital,
			lora_vital_len(&mon_lora_vital), LORA_TX_TIMEOUT)) {
		++mon_lora_frames;
	}

	/* Bounded worst case, not a measurement: age is an upper bound on how long
	 * the poll sat unnoticed. If this ever approaches LORA_POLL_SLOT_MS the
	 * superloop, not the radio, is the thing to fix. */
	mon_lora_reply_ms = age + (HAL_GetTick() - now);
}

/* Keeps a requested RFID scan running and converts a found UID to the ASCII hex
 * the wire carries. Returns immediately when no scan is pending, so the cost in
 * the common case is one flag test.
 *
 * Retries every pass while a scan is pending, up to RFID_SCAN_WINDOW_MS, because
 * the ESP32 asks once but the operator taps the card seconds later -- one poll of
 * an empty field would just report NO_CARD and give up. Stops on the first tag
 * found, so a card left on the reader is not read repeatedly.
 *
 * Each attempt blocks for up to ~120 ms inside Pn532_Service, which is safe here
 * for the reason its header documents: ADC and PPG samples arrive by interrupt,
 * so a stalled superloop delays processing rather than losing data, and the
 * margin is the 4 s ECG window. Note that the ESP32's snapshot poll also pauses
 * for that long -- its 2 s frozen-seq warning has plenty of headroom, but this
 * is why scanning is request-scoped and not a background free-run.
 *
 * Why ASCII rather than the raw bytes: TB_REG_RFID is a char array the ESP32
 * puts straight on the screen and into its session record, and a 4-byte binary
 * UID containing 0x00 would truncate there. Hex is twice as long and always
 * printable. 10-byte UIDs give 20 characters, well inside TB_RFID_MAX (31).
 *
 * The tag is then STICKY: it keeps being published until the next START_SCAN
 * clears it. The ESP32 consumes it as a one-shot (ui_mock_rfid_ready clears its
 * own copy), so the card does not have to stay in the field while the operator
 * works through the following screens. */
static void ServiceRfid(void) {
	Pn532_Tag tag;
	uint8_t status;

	if (!rfid_scanning) {
		return; /* idle; leave the previously published tag in place */
	}

	/* Subtraction, not (start + window) > now: HAL_GetTick wraps at 2^32 ms and
	 * unsigned subtraction stays correct across the wrap. */
	if ((HAL_GetTick() - rfid_scan_started_ms) >= RFID_SCAN_WINDOW_MS) {
		rfid_scanning = 0U;
		return;
	}

	Pn532_RequestScan();
	status = Pn532_Service(&tag);

	++mon_rfid_scans;
	mon_rfid_status = status;

	/* Mirror the diagnostics on every attempt, success or not: the stage after a
	 * success is the useful baseline for reading the failures. */
	mon_rfid_stage = Pn532_LastStage();
	{
		uint8_t raw[PN532_RAW_MAX];
		const uint8_t n = Pn532_LastRaw(raw, sizeof(raw));
		for (uint8_t i = 0; i < PN532_RAW_MAX; ++i) {
			mon_rfid_raw[i] = (i < n) ? raw[i] : 0U;
		}
		mon_rfid_raw_len = n;
	}

	if (status != PN532_FOUND) {
		/* Keep retrying, and deliberately keep rfid_ascii: a failed poll must
		 * not blank an identifier the operator is already looking at.
		 * mon_rfid_status says what failed, mon_rfid_stage says where, and
		 * mon_rfid_raw says what the module sent instead. */
		return;
	}

	rfid_scanning = 0U;
	++mon_rfid_found;
	mon_rfid_uid_len = tag.uid_len;
	for (uint8_t i = 0; i < PN532_UID_MAX; ++i) {
		mon_rfid_uid[i] = (i < tag.uid_len) ? tag.uid[i] : 0U;
	}
	/* No Pn532_PackUid() here any more: the LoRa packet used to carry a 4-byte
	 * binary UID and now carries the same ASCII hex the ESP32 gets, so both links
	 * name the patient identically and the station needs no second format. */

	static const char k_hex[] = "0123456789ABCDEF";
	/* Two hex characters per UID byte always fits: the longest UID ISO14443-3
	 * allows is 10 bytes = 20 characters, and TB_REG_RFID holds 31. Asserted at
	 * compile time rather than clamped at run time, so if either constant ever
	 * moves the build fails instead of silently truncating an identifier. The
	 * LoRa field is sized to the 20 rather than the 31, so it is checked too --
	 * a truncated identifier there would attach telemetry to the wrong patient
	 * on the station side only, which is the hardest kind of bug to notice. */
	_Static_assert((PN532_UID_MAX * 2U) <= TB_RFID_MAX,
			"UID hex does not fit TB_REG_RFID");
	_Static_assert((PN532_UID_MAX * 2U) <= LORA_VITAL_RFID_MAX,
			"UID hex does not fit lora_vital_t.victim_rfid");
	for (uint8_t i = 0; i < tag.uid_len; ++i) {
		rfid_ascii[i * 2U] = k_hex[(tag.uid[i] >> 4) & 0x0FU];
		rfid_ascii[(i * 2U) + 1U] = k_hex[tag.uid[i] & 0x0FU];
	}
	rfid_ascii_len = (uint8_t) (tag.uid_len * 2U);
}

/* Polls the buttons and hands the ESP32 a fresh snapshot. Called every superloop
 * pass (~10ms), which sets both the button response time and the rate at which
 * the sequence counter advances.
 *
 * Reads the mon_* globals rather than taking arguments: they are already the
 * one place every produced value lands, so a second parameter list would be a
 * second thing to keep in sync. They are volatile and not read atomically, so a
 * float could in principle tear; only the integers below go on the wire, and a
 * 16-bit load on Cortex-M4 is single-instruction. */
static void PublishToEsp32(void) {
	uint8_t pins = 0;
	uint8_t flags = 0;
	uint8_t sensors = 0;

	/* Raw pin levels, LSB = BUTTON_1. Pressed reads LOW (input + pull-up);
	 * tb_buttons_poll owns that inversion, so nothing here knows about it. */
	if (HAL_GPIO_ReadPin(BUTTON_1_GPIO_Port, BUTTON_1_Pin) == GPIO_PIN_SET) {
		pins |= 0x01U;
	}
	if (HAL_GPIO_ReadPin(BUTTON_2_GPIO_Port, BUTTON_2_Pin) == GPIO_PIN_SET) {
		pins |= 0x02U;
	}
	if (HAL_GPIO_ReadPin(BUTTON_3_GPIO_Port, BUTTON_3_Pin) == GPIO_PIN_SET) {
		pins |= 0x04U;
	}
	if (HAL_GPIO_ReadPin(BUTTON_4_GPIO_Port, BUTTON_4_Pin) == GPIO_PIN_SET) {
		pins |= 0x08U;
	}
	mon_buttons = tb_buttons_poll(&btn_state, pins);

	/* Per-vital validity. A zero reading means "no reading" in every one of
	 * these, which is why each gets its own bit: a finger off the MAX30102
	 * must not invalidate a perfectly good ECG heart rate.
	 *
	 * Driven from mon_rate_bpm/mon_rate_is_pr rather than re-deciding from
	 * mon_hr_bpm here. The arbitration in the superloop can drop an ECG rate
	 * that disagrees with the PPG, and a second copy of the rule would light
	 * TB_SENSOR_ECG for a rate that never reached the wire. */
	if (mon_rate_bpm > 0U) {
		flags |= TB_FLAG_HR_VALID;
		if (mon_rate_is_pr != 0U) {
			/* A pulse rate is a valid rate, so the number is published -- but
			 * TB_SENSOR_ECG is NOT, because the ECG did not produce it and a
			 * status dot claiming a working ECG would send someone looking for
			 * a fault that is already known. */
			flags |= TB_FLAG_HR_FROM_PPG;
		} else {
			sensors |= TB_SENSOR_ECG;
		}
	}
	if (mon_spo2_valid != 0U) {
		flags |= TB_FLAG_SPO2_VALID;
	}
	/* Waveform trust, separate from the percentage above: the ESP32 runs its own
	 * PPG processing on the ring and would otherwise find a heart rate in the
	 * ~2000 counts of ambient light the sensor reads with nothing on it. */
	if (mon_ppg_contact != 0U) {
		flags |= TB_FLAG_PPG_CONTACT;
	}
	/* Health is "the sensor is being read", NOT "a finger is on it" -- an empty
	 * sensor is the normal idle state and must not show as a dead module on the
	 * status dots, the same rule TB_SENSOR_RFID follows below. mon_red_raw is
	 * nonzero as soon as one FIFO word has arrived, and the no-finger reading is
	 * ~2000 counts rather than 0, so this distinguishes "nothing on the sensor"
	 * from "the MAX30102 never answered". Driving it from mon_spo2_pct instead,
	 * as it was until 2026-08-18, made a correctly-idle sensor go dark. */
	if (mon_red_raw > 0U) {
		sensors |= TB_SENSOR_MAX30102;
	}
	if (ResolvedRespBrpm() > 0.0f) {
		sensors |= TB_SENSOR_MIC;
	}
	/* A BREATHING RATE EXISTS, from whichever source has one -- the mic if it is
	 * fitted, otherwise the operator's typed value at TB_REG_HOST_RR. The bit and
	 * the LoRa rr field are driven from the same WireRespBrpm(), so the station
	 * cannot see a rate without the bit or a bit without a rate.
	 *
	 * TB_SENSOR_MIC stays above with the microphone, NOT here: the sensor byte is
	 * per-module health and a typed number proves nothing about a mic that is not
	 * fitted. tb_regs.h's TB_FLAG_RR_VALID comment carries the rest of the
	 * argument, including how this reverts when the mic PCB ships.
	 *
	 * TB_REG_RR_X10 is deliberately left showing the mic's own value (0 today) --
	 * see WireRespBrpm(). So this flag can be set with that register at 0, which is
	 * the one asymmetry in the read block and the point of the whole arrangement:
	 * the ESP32 must not read an operator's estimate back as a measurement. */
	if (WireRespBrpm() > 0U) {
		flags |= TB_FLAG_RR_VALID;
	}
	/* BP is the ESP32's own ML prediction coming back across the link, not a
	 * measurement this board takes -- there is no cuff, and PA2 is the breathing
	 * microphone, so the MPX5010 path is long gone. The bit tracks mon_bp_valid,
	 * i.e. "a pair that passed tb_bp_pair_valid() is standing", so it is clear
	 * from boot until the model first speaks and the ESP32's SVM sees a missing
	 * feature rather than a fabricated 0/0.
	 *
	 * Set from the same variables PackTelemetry() reads, so the flag and the
	 * numbers cannot disagree between the two links -- the failure that would
	 * cause is a station publishing a pressure the screen says is invalid. */
	if (mon_bp_valid != 0U) {
		flags |= TB_FLAG_BP_VALID;
	}
	/* "LoRa working" means the module answers AND this board has an address on
	 * the channel. A UID missing from the table resolves to mon_node_id 0, and
	 * such a board is radios-healthy but cannot appear on the dashboard -- which
	 * is exactly what the status dot should say, and the one visible trace of a
	 * provisioning mistake that is otherwise silent by design. */
	if ((lora_status == LORA_OK) && (mon_node_id != 0U)) {
		sensors |= TB_SENSOR_LORA;
	}
	/* RFID health is "the module answered", not "a card is present": an empty
	 * field is the normal state and must not show as a dead sensor on the
	 * ESP32's status dots. PN532_ERR_* and the never-scanned IDLE both leave it
	 * clear, so the dot only lights once the reader has actually been reached. */
	if ((mon_rfid_status == PN532_FOUND) || (mon_rfid_status == PN532_NO_CARD)) {
		sensors |= TB_SENSOR_RFID;
	}

	/* Kept for the LoRa packet, which needs exactly these two bytes and must not
	 * re-derive them: two copies of "is this reading real" would eventually
	 * disagree, and the ESP32 and the station would then triage on different
	 * facts. Also the pair CubeMonitor wants when a vital looks stuck. */
	mon_flags = flags;
	mon_sensor_ok = sensors;

	tb_slave_publish(flags, mon_buttons, mon_rate_bpm,
			(uint16_t) (mon_spo2_pct + 0.5f),
			/* The MICROPHONE's rate only, still 0 today, and deliberately NOT
			 * WireRespBrpm(): echoing the operator's typed value here would let
			 * the ESP32 read its own estimate back as a measurement, with the
			 * provenance of a sensor. tb_regs.h says the same at
			 * TB_REG_HOST_RR. */
			(uint16_t) ((ResolvedRespBrpm() * 10.0f) + 0.5f),
			/* Echoed back, like the battery below and for the same reason:
			 * TB_REG_BP_SYS/BP_DIA are "the patient's blood pressure" to
			 * everyone reading this block, and there is exactly one source for
			 * it. Echoing also makes the write verifiable with `i2creg` -- if
			 * these read back 0/0 after the ESP32 wrote a pair, the write was
			 * rejected by tb_bp_pair_valid() and mon_bp_writes_rejected says so.
			 * Same variables PackTelemetry() uses, so both links agree. */
			mon_bp_sys,
			mon_bp_dia,
			/* Echoed back rather than left at 0xFF: TB_REG_BATTERY is "the
			 * node's battery" to everyone reading this block, and there is
			 * exactly one gauge on this node. Echoing also makes the write
			 * verifiable with `i2creg` -- if it reads back 0xFF, the ESP32's
			 * write never landed. */
			tb_slave_host_battery(),
			sensors, rfid_ascii, rfid_ascii_len);
}
/* USER CODE END 4 */

void Error_Handler(void)
{
  /* USER CODE BEGIN Error_Handler_Debug */
	/* User can add his own implementation to report the HAL error return state */

	/* Let go of I2C2 before going quiet. Those pins are the ESP32's only I2C
	 * bus -- GT911 touch, TCA9554 display expander, SW6106 PMIC -- and an
	 * enabled I2C slave whose interrupts never run holds SCL low from the first
	 * address match onwards. The ESP32 then dies in bsp_display_start() on the
	 * GT911 probe, before a single LVGL screen is loaded, which on the panel
	 * looks like "the LCD is always white when the STM32 is connected". Clearing
	 * PE releases SCL and SDA, so a dead STM32 costs vitals, not the whole UI.
	 *
	 * Guarded because Error_Handler() is also reachable from SystemClock_Config,
	 * before MX_I2C2_Init() has set hi2c2.Instance -- dereferencing NULL there
	 * would trade this hang for a HardFault. */
	if (hi2c2.Instance != NULL) {
		__HAL_I2C_DISABLE(&hi2c2);
	}

	__disable_irq();
	while (1) {
	}
  /* USER CODE END Error_Handler_Debug */
}
